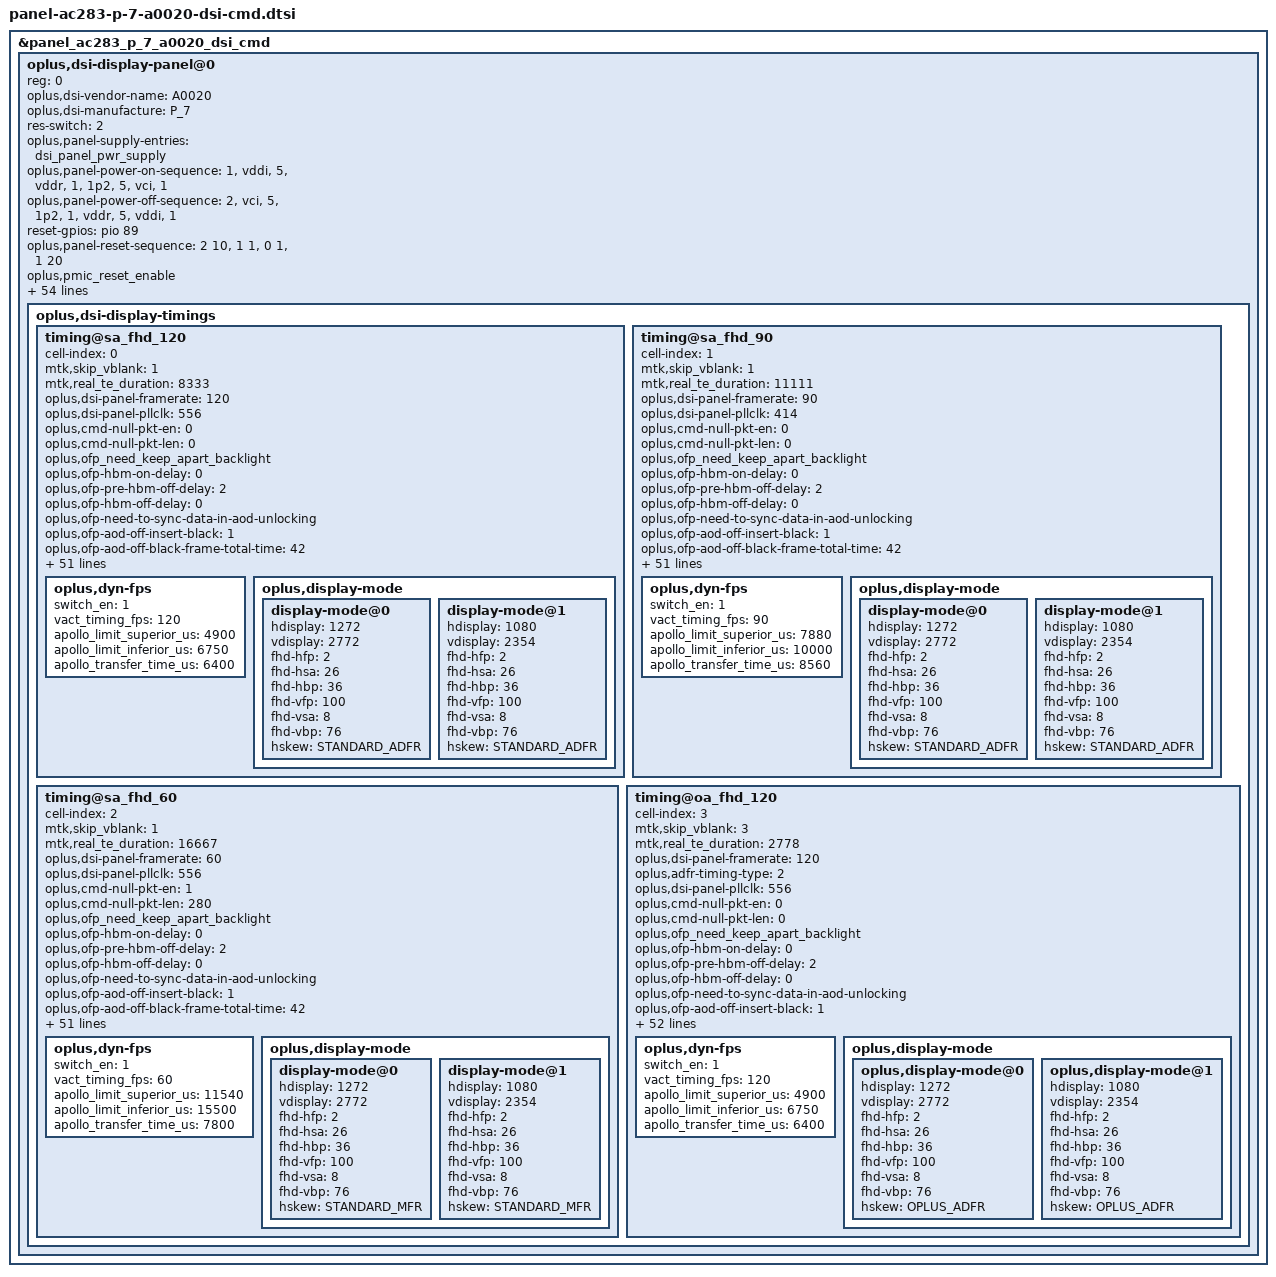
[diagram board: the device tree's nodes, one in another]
&panel_ac283_p_7_a0020_dsi_cmd {
	oplus,dsi-display-panel@0 {
		reg = <0>;
		oplus,dsi-vendor-name = "A0020";
		oplus,dsi-manufacture = "P_7";
		/* round corner */
		#include "panel-ac283-p-7-a0020-dsi-cmd-round-corner.dtsi"
		oplus,dsi-display-timings {
			timing@sa_fhd_120 {
				cell-index = <0>;
				mtk,skip_vblank = <1>;
				mtk,real_te_duration = <8333>;
				oplus,dsi-panel-framerate = <120>;
				oplus,dsi-panel-pllclk = <556>;
				oplus,cmd-null-pkt-en = <0>;
				oplus,cmd-null-pkt-len = <0>;
				/* OPLUS_FEATURE_DISPLAY_ONSCREENFINGERPRINT */
				oplus,ofp_need_keep_apart_backlight;
				oplus,ofp-hbm-on-delay = <0>;
				oplus,ofp-pre-hbm-off-delay = <2>;
				oplus,ofp-hbm-off-delay = <0>;
				oplus,ofp-need-to-sync-data-in-aod-unlocking;
				oplus,ofp-aod-off-insert-black = <1>;
				oplus,ofp-aod-off-black-frame-total-time = <42>;
				#include "panel-ac283-p-7-a0020-dsi-cmd-common.dtsi"
				oplus,dsi-timing-switch-command = [
					39 00 00 40 00 00 04 FF 5A A5 00
					15 00 00 40 00 00 02 60 00
					15 00 00 40 00 00 02 7D 00
					39 00 00 40 00 00 04 FF 5A A5 2D
					39 00 00 40 00 00 03 83 00 00
					15 00 00 00 00 00 02 F2 00
				];
				oplus,dsi-timing-switch-1pulse-command = [
				];
				oplus,dsi-on-command = [
					39 00 00 40 00 00 04 FF 5A A5 08
					15 00 00 40 00 00 02 C8 62 //OTP don’t reload
					39 00 00 40 00 00 04 FF 5A A5 21
					15 00 00 40 00 00 02 A4 38 //Flash reload
					39 00 00 40 00 00 04 FF 5A A5 23
					15 00 00 40 00 00 02 85 15 //BC reload by OTP
					39 00 00 40 00 00 04 FF 5A A5 01
					15 00 00 40 00 00 02 FB 08 //Multi TE
					// odc impro
					39 00 00 40 00 00 04 FF 5A A5 49
					39 00 00 40 00 00 0C 80 00 08 0C 1C 3C 7C 8C CC 0C 00 01
					39 00 00 40 00 00 11 81 00 00 9E 00 E5 00 6C 01 41 02 A6 03 8B 05 DD 06
					39 00 00 40 00 00 13 82 00 00 9E 00 E5 00 6C 01 41 02 A6 03 8B 05 DD 06 00 00
					15 00 00 40 00 00 02 83 07
					15 00 00 40 00 00 02 84 14
					39 00 00 40 00 00 04 85 80 00 02
					39 00 00 40 00 00 04 86 80 00 02
					39 00 00 40 00 00 04 A0 40 40 40
					39 00 00 40 00 00 04 A1 40 40 40
					39 00 00 40 00 00 04 A2 40 40 40
					15 00 00 40 00 00 02 A6 3F
					15 00 00 40 00 00 02 A7 07
					15 00 00 40 00 00 02 AD 01
					15 00 00 40 00 00 02 AE 08
					15 00 00 40 00 00 02 AF 08
					15 00 00 40 00 00 02 D9 02
					15 00 00 40 00 00 02 DA F7
					15 00 00 40 00 00 02 DB 9C
					15 00 00 40 00 00 02 DC 03
					15 00 00 40 00 00 02 DF 06
					15 00 00 40 00 00 02 E0 01
					39 00 00 40 00 00 04 FF 5A A5 5A
					39 00 00 40 00 00 04 80 00 00 00
					39 00 00 40 00 00 04 81 00 00 00
					39 00 00 40 00 00 04 82 00 00 00
					39 00 00 40 00 00 04 83 10 10 10
					39 00 00 40 00 00 04 84 00 00 00
					39 00 00 40 00 00 04 85 00 00 00
					39 00 00 40 00 00 04 86 48 02 30
					39 00 00 40 00 00 04 87 08 02 04
					39 00 00 40 00 00 04 88 08 02 04
					39 00 00 40 00 00 04 89 08 02 04
					39 00 00 40 00 00 04 8A 30 00 10
					39 00 00 40 00 00 04 8B 10 10 10
					39 00 00 40 00 00 04 8C 1A 1E 16
					39 00 00 40 00 00 04 8D 10 06 04
					39 00 00 40 00 00 04 8E 0B 06 0E
					39 00 00 40 00 00 04 8F 28 F9 0D
					39 00 00 40 00 00 04 90 12 10 10
					39 00 00 40 00 00 04 91 1D 12 15
					39 00 00 40 00 00 04 92 10 05 18
					39 00 00 40 00 00 04 93 08 FF 10
					39 00 00 40 00 00 04 94 02 FF 02
					39 00 00 40 00 00 04 95 20 0D 10
					39 00 00 40 00 00 04 96 0A 0D 0D
					39 00 00 40 00 00 04 97 0A 0D 0D
					39 00 00 40 00 00 04 98 12 14 18
					39 00 00 40 00 00 04 99 14 0E 1E
					39 00 00 40 00 00 04 9A 0A 06 0E
					39 00 00 40 00 00 04 9B 02 02 02
					39 00 00 40 00 00 04 9C 15 10 10
					39 00 00 40 00 00 04 9D 12 14 2E
					39 00 00 40 00 00 04 9E 10 26 20
					39 00 00 40 00 00 04 9F 1D 14 20
					39 00 00 40 00 00 04 A0 14 0A 1A
					39 00 00 40 00 00 04 A1 14 0A 10
					39 00 00 40 00 00 04 A2 12 08 12
					39 00 00 40 00 00 04 A3 02 02 02
					39 00 00 40 00 00 04 A4 00 00 00
					39 00 00 40 00 00 04 A5 06 F6 F5
					39 00 00 40 00 00 04 A6 00 00 00
					39 00 00 40 00 00 04 A7 02 00 00
					39 00 00 40 00 00 04 A8 00 02 00
					39 00 00 40 00 00 04 A9 00 02 00
					39 00 00 40 00 00 04 AA 08 F5 F0
					39 00 00 40 00 00 04 AB 06 06 0A
					39 00 00 40 00 00 04 AC 08 07 06
					39 00 00 40 00 00 04 AD 02 02 04
					39 00 00 40 00 00 04 AE 12 14 12
					39 00 00 40 00 00 04 AF 18 16 16
					39 00 00 40 00 00 04 B0 16 16 14
					39 00 00 40 00 00 04 B1 04 02 10
					39 00 00 40 00 00 04 B2 02 02 02
					39 00 00 40 00 00 04 B3 20 1A 2C
					39 00 00 40 00 00 04 B4 1C 16 1A
					39 00 00 40 00 00 04 B5 12 10 12
					39 00 00 40 00 00 04 B6 06 02 14
					39 00 00 40 00 00 04 B7 F6 04 02
					39 00 00 40 00 00 04 B8 F6 04 02
					39 00 00 40 00 00 04 B9 06 0D 0D
					39 00 00 40 00 00 04 BA 12 10 13
					39 00 00 40 00 00 04 BB 12 16 16
					39 00 00 40 00 00 04 BC 12 10 16
					39 00 00 40 00 00 04 BD 12 0E 12
					39 00 00 40 00 00 04 BE F6 06 02
					39 00 00 40 00 00 04 BF F6 06 02
					39 00 00 40 00 00 04 C0 12 12 12
					39 00 00 40 00 00 04 C1 12 16 10
					39 00 00 40 00 00 04 C2 12 16 1C
					39 00 00 40 00 00 04 C3 12 10 1C
					39 00 00 40 00 00 04 C4 18 18 1C
					39 00 00 40 00 00 04 C5 12 0E 16
					39 00 00 40 00 00 04 C6 16 1A 12
					39 00 00 40 00 00 04 C7 02 02 02
					39 00 00 40 00 00 04 C8 00 00 00
					39 00 00 40 00 00 04 C9 10 FC 0A
					39 00 00 40 00 00 04 CA 00 00 00
					39 00 00 40 00 00 04 CB 10 F6 0A
					39 00 00 40 00 00 04 CC 0A 08 00
					39 00 00 40 00 00 04 CD 08 06 00
					39 00 00 40 00 00 04 CE 0D 00 0A
					39 00 00 40 00 00 04 CF 04 04 04
					39 00 00 40 00 00 04 D0 04 06 06
					39 00 00 40 00 00 04 D1 02 04 04
					39 00 00 40 00 00 04 D2 16 16 14
					39 00 00 40 00 00 04 D3 16 14 14
					39 00 00 40 00 00 04 D4 14 14 12
					39 00 00 40 00 00 04 D5 10 10 10
					39 00 00 40 00 00 04 D6 02 02 02
					39 00 00 40 00 00 04 D7 12 18 16
					39 00 00 40 00 00 04 D8 12 16 12
					39 00 00 40 00 00 04 D9 10 16 12
					39 00 00 40 00 00 04 DA 0D 0A 0D
					39 00 00 40 00 00 04 DB F4 04 04
					39 00 00 40 00 00 04 DC F4 04 04
					39 00 00 40 00 00 04 DD 0D 12 10
					39 00 00 40 00 00 04 DE 0D 10 12
					39 00 00 40 00 00 04 DF 08 10 10
					39 00 00 40 00 00 04 E0 0D 20 18
					39 00 00 40 00 00 04 E1 08 14 10
					39 00 00 40 00 00 04 E2 F4 04 04
					39 00 00 40 00 00 04 E3 F4 04 04
					39 00 00 40 00 00 04 E4 0D 16 14
					39 00 00 40 00 00 04 E5 0D 12 12
					39 00 00 40 00 00 04 E6 0D 10 12
					39 00 00 40 00 00 04 E7 0D 10 12
					39 00 00 40 00 00 04 E8 0D 12 14
					39 00 00 40 00 00 04 E9 0A 10 10
					39 00 00 40 00 00 04 EA 06 10 0A
					39 00 00 40 00 00 04 EB 02 04 02
					39 00 00 40 00 00 04 FF 5A A5 5B
					39 00 00 40 00 00 04 80 00 00 00
					39 00 00 40 00 00 04 81 0D FC 02
					39 00 00 40 00 00 04 82 04 02 04
					39 00 00 40 00 00 04 83 0D 00 02
					39 00 00 40 00 00 04 84 04 04 03
					39 00 00 40 00 00 04 85 04 04 03
					39 00 00 40 00 00 04 86 03 00 01
					39 00 00 40 00 00 04 87 06 05 06
					39 00 00 40 00 00 04 88 05 03 06
					39 00 00 40 00 00 04 89 02 03 06
					39 00 00 40 00 00 04 8A 12 1A 14
					39 00 00 40 00 00 04 8B 14 18 14
					39 00 00 40 00 00 04 8C 14 18 14
					39 00 00 40 00 00 04 8D 10 12 0E
					39 00 00 40 00 00 04 8E 08 0A 08
					39 00 00 40 00 00 04 8F 10 34 2C
					39 00 00 40 00 00 04 90 10 1E 1A
					39 00 00 40 00 00 04 91 10 1E 18
					39 00 00 40 00 00 04 92 10 18 14
					39 00 00 40 00 00 04 93 F0 06 06
					39 00 00 40 00 00 04 94 F0 06 06
					39 00 00 40 00 00 04 95 06 16 16
					39 00 00 40 00 00 04 96 10 18 10
					39 00 00 40 00 00 04 97 12 16 16
					39 00 00 40 00 00 04 98 12 1E 16
					39 00 00 40 00 00 04 99 0D 14 18
					39 00 00 40 00 00 04 9A F0 06 06
					39 00 00 40 00 00 04 9B F0 06 06
					39 00 00 40 00 00 04 9C 14 18 14
					39 00 00 40 00 00 04 9D 16 16 12
					39 00 00 40 00 00 04 9E 0D 16 1E
					39 00 00 40 00 00 04 9F 0D 12 12
					39 00 00 40 00 00 04 A0 0D 16 18
					39 00 00 40 00 00 04 A1 18 16 16
					39 00 00 40 00 00 04 A2 02 02 02
					39 00 00 40 00 00 04 A3 02 02 02
					39 00 00 40 00 00 04 A4 05 00 04
					39 00 00 40 00 00 04 A5 08 03 02
					39 00 00 40 00 00 04 A6 02 02 00
					39 00 00 40 00 00 04 A7 06 03 02
					39 00 00 40 00 00 04 A8 02 02 00
					39 00 00 40 00 00 04 A9 02 02 00
					39 00 00 40 00 00 04 AA 06 06 06
					39 00 00 40 00 00 04 AB 06 06 04
					39 00 00 40 00 00 04 AC 04 06 04
					39 00 00 40 00 00 04 AD 02 02 02
					39 00 00 40 00 00 04 AE 12 12 14
					39 00 00 40 00 00 04 AF 14 16 14
					39 00 00 40 00 00 04 B0 12 14 12
					39 00 00 40 00 00 04 B1 04 02 0E
					39 00 00 40 00 00 04 B2 04 02 08
					39 00 00 40 00 00 04 B3 20 28 20
					39 00 00 40 00 00 04 B4 0D 16 12
					39 00 00 40 00 00 04 B5 0D 10 10
					39 00 00 40 00 00 04 B6 F6 02 02
					39 00 00 40 00 00 04 B7 F0 06 02
					39 00 00 40 00 00 04 B8 F0 06 02
					39 00 00 40 00 00 04 B9 0D 14 16
					39 00 00 40 00 00 04 BA 0F 12 16
					39 00 00 40 00 00 04 BB 14 16 12
					39 00 00 40 00 00 04 BC 04 08 08
					39 00 00 40 00 00 04 BD F6 02 10
					39 00 00 40 00 00 04 BE F0 06 02
					39 00 00 40 00 00 04 BF F0 06 02
					39 00 00 40 00 00 04 C0 10 16 12
					39 00 00 40 00 00 04 C1 14 16 18
					39 00 00 40 00 00 04 C2 16 14 10
					39 00 00 40 00 00 04 C3 10 12 16
					39 00 00 40 00 00 04 C4 02 0A 16
					39 00 00 40 00 00 04 C5 00 02 16
					39 00 00 40 00 00 04 C6 00 0A 14
					39 00 00 40 00 00 04 C7 02 02 02
					39 00 00 40 00 00 04 C8 06 00 06
					39 00 00 40 00 00 04 C9 05 02 02
					39 00 00 40 00 00 04 CA 00 00 00
					39 00 00 40 00 00 04 CB 04 04 03
					39 00 00 40 00 00 04 CC 02 02 02
					39 00 00 40 00 00 04 CD 00 00 00
					39 00 00 40 00 00 04 CE 0C 0C 0E
					39 00 00 40 00 00 04 CF 06 06 06
					39 00 00 40 00 00 04 D0 04 06 04
					39 00 00 40 00 00 04 D1 02 02 02
					39 00 00 40 00 00 04 D2 12 12 12
					39 00 00 40 00 00 04 D3 12 12 12
					39 00 00 40 00 00 04 D4 14 16 14
					39 00 00 40 00 00 04 D5 06 06 0A
					39 00 00 40 00 00 04 D6 02 02 06
					39 00 00 40 00 00 04 D7 1D 24 1E
					39 00 00 40 00 00 04 D8 16 1E 1A
					39 00 00 40 00 00 04 D9 12 1A 18
					39 00 00 40 00 00 04 DA 02 04 10
					39 00 00 40 00 00 04 DB FD 02 0A
					39 00 00 40 00 00 04 DC FD 00 00
					39 00 00 40 00 00 04 DD 12 18 1D
					39 00 00 40 00 00 04 DE 14 1B 1E
					39 00 00 40 00 00 04 DF 10 1A 1D
					39 00 00 40 00 00 04 E0 10 1A 14
					39 00 00 40 00 00 04 E1 02 0A 06
					39 00 00 40 00 00 04 E2 FD 02 02
					39 00 00 40 00 00 04 E3 FD 02 02
					39 00 00 40 00 00 04 E4 14 18 1C
					39 00 00 40 00 00 04 E5 10 1A 1A
					39 00 00 40 00 00 04 E6 1A 14 16
					39 00 00 40 00 00 04 E7 18 16 1C
					39 00 00 40 00 00 04 E8 14 10 10
					39 00 00 40 00 00 04 E9 0C 0E 12
					39 00 00 40 00 00 04 EA 14 12 10
					39 00 00 40 00 00 04 EB 02 02 02
					39 00 00 40 00 00 04 FF 5A A5 5C
					39 00 00 40 00 00 04 80 03 01 00
					39 00 00 40 00 00 04 81 04 02 02
					39 00 00 40 00 00 04 82 00 00 00
					39 00 00 40 00 00 04 83 01 03 02
					39 00 00 40 00 00 04 84 02 02 02
					39 00 00 40 00 00 04 85 00 00 00
					39 00 00 40 00 00 04 86 0E 10 0E
					39 00 00 40 00 00 04 87 06 06 06
					39 00 00 40 00 00 04 88 06 06 06
					39 00 00 40 00 00 04 89 02 02 02
					39 00 00 40 00 00 04 8A 16 16 14
					39 00 00 40 00 00 04 8B 16 18 14
					39 00 00 40 00 00 04 8C 14 16 12
					39 00 00 40 00 00 04 8D 0E 0E 0C
					39 00 00 40 00 00 04 8E 06 08 06
					39 00 00 40 00 00 04 8F 10 14 1C
					39 00 00 40 00 00 04 90 16 1E 18
					39 00 00 40 00 00 04 91 14 1A 16
					39 00 00 40 00 00 04 92 0D 12 10
					39 00 00 40 00 00 04 93 F2 06 04
					39 00 00 40 00 00 04 94 F2 06 04
					39 00 00 40 00 00 04 95 12 12 18
					39 00 00 40 00 00 04 96 12 10 1E
					39 00 00 40 00 00 04 97 12 18 1E
					39 00 00 40 00 00 04 98 12 1D 20
					39 00 00 40 00 00 04 99 12 1D 18
					39 00 00 40 00 00 04 9A F2 06 04
					39 00 00 40 00 00 04 9B F2 06 04
					39 00 00 40 00 00 04 9C 12 16 12
					39 00 00 40 00 00 04 9D 18 1E 12
					39 00 00 40 00 00 04 9E 14 1C 12
					39 00 00 40 00 00 04 9F 10 12 16
					39 00 00 40 00 00 04 A0 12 12 1C
					39 00 00 40 00 00 04 A1 12 12 0E
					39 00 00 40 00 00 04 A2 0E 10 0C
					39 00 00 40 00 00 04 A3 06 08 06
					39 00 00 40 00 00 04 A4 02 00 00
					39 00 00 40 00 00 04 A5 02 02 02
					39 00 00 40 00 00 04 A6 00 00 00
					39 00 00 40 00 00 04 A7 01 01 00
					39 00 00 40 00 00 04 A8 02 02 02
					39 00 00 40 00 00 04 A9 00 00 00
					39 00 00 40 00 00 04 AA 04 06 05
					39 00 00 40 00 00 04 AB 08 08 06
					39 00 00 40 00 00 04 AC 06 06 06
					39 00 00 40 00 00 04 AD 04 06 02
					39 00 00 40 00 00 04 AE 14 16 16
					39 00 00 40 00 00 04 AF 12 1A 14
					39 00 00 40 00 00 04 B0 14 16 12
					39 00 00 40 00 00 04 B1 04 04 0C
					39 00 00 40 00 00 04 B2 06 02 06
					39 00 00 40 00 00 04 B3 18 1A 1C
					39 00 00 40 00 00 04 B4 1A 1E 18
					39 00 00 40 00 00 04 B5 18 1A 14
					39 00 00 40 00 00 04 B6 06 04 0E
					39 00 00 40 00 00 04 B7 00 02 02
					39 00 00 40 00 00 04 B8 FE 00 00
					39 00 00 40 00 00 04 B9 0D 1D 1C
					39 00 00 40 00 00 04 BA 12 1D 1E
					39 00 00 40 00 00 04 BB 14 13 15
					39 00 00 40 00 00 04 BC 04 0C 0B
					39 00 00 40 00 00 04 BD 04 0C 0B
					39 00 00 40 00 00 04 BE FE 02 02
					39 00 00 40 00 00 04 BF FE 02 02
					39 00 00 40 00 00 04 C0 12 18 16
					39 00 00 40 00 00 04 C1 16 12 10
					39 00 00 40 00 00 04 C2 1C 16 1C
					39 00 00 40 00 00 04 C3 10 14 16
					39 00 00 40 00 00 04 C4 14 0A 1C
					39 00 00 40 00 00 04 C5 0E 08 10
					39 00 00 40 00 00 04 C6 0A 04 0A
					39 00 00 40 00 00 04 C7 00 00 00
					39 00 00 40 00 00 04 C8 04 04 04
					39 00 00 40 00 00 04 C9 0A 04 04
					39 00 00 40 00 00 04 CA 0A 04 04
					39 00 00 40 00 00 04 CB 0A 04 04
					39 00 00 40 00 00 04 CC 00 00 00
					39 00 00 40 00 00 04 CD 01 01 01
					39 00 00 40 00 00 04 CE 02 00 00
					39 00 00 40 00 00 04 CF 02 01 01
					39 00 00 00 00 00 04 FF 5A A5 00
					// ctb impro
					39 00 00 40 00 00 04 FF 5A A5 31
					39 00 00 40 00 00 0B 90 02 03 05 07 0A 02 03 05 07 0A
					39 00 00 40 00 00 19 8C 21 13 0C 0B 08 04 00 00 00 00 00 00 00 00 00 00 00 00 00 00 00 00 00 00
					39 00 00 40 00 00 1A 8D 16 0A 06 00 00 00 00 00 00 00 00 00 00 00 00 00 00 00 00 00 00 00 00 00 00
					39 00 00 40 00 00 09 8F 40 40 40 40 40 40 40 40
					15 00 00 40 00 00 02 D0 81
					39 00 00 40 00 00 13 80 F0 92 24 18 02 FE E8 DC 6E E0 10 0A 05 00 00 FA F6 F3
					39 00 00 40 00 00 13 81 F0 5C 24 16 02 FE EA DC A4 E0 0A 09 05 00 00 FE FB F0
					39 00 00 40 00 00 13 82 F0 48 24 11 02 FE EF DC B8 E0 0E 09 05 00 00 FF F7 F4
					39 00 00 40 00 00 13 83 F0 44 2C 10 02 FE F0 D4 BC E0 13 0D 05 00 00 FF FA F8
					39 00 00 40 00 00 13 86 F0 92 24 18 02 FE E8 DC 6E E0 10 0A 05 00 00 FA F6 F3
					39 00 00 40 00 00 13 87 F0 5C 24 16 02 FE EA DC A4 E0 0A 09 05 00 00 FE FB F0
					39 00 00 40 00 00 13 88 F0 48 24 11 02 FE EF DC B8 E0 0E 09 05 00 00 FF F7 F4
					39 00 00 40 00 00 13 89 F0 44 2C 10 02 FE F0 D4 BC E0 13 0D 05 00 00 FF FA F8
					15 00 00 40 00 00 02 D0 80
					39 00 00 00 01 00 04 FF 5A A5 00
					// te shift on
					39 00 00 40 00 00 04 FF 5A A5 02
					39 00 00 40 00 00 03 AB AF 82
					// ddic corner Hole
					39 00 00 40 00 00 04 FF 5A A5 13
					39 00 00 40 00 00 02 F9 4C //HOLE OFF
					39 00 00 40 00 00 04 FF 5A A5 17
					15 00 00 40 00 00 02 A0 0E //RCN OFF
					// pps table
					39 00 00 40 00 00 04 FF 5A A5 07
					15 00 00 40 00 00 02 8A 01
					39 00 00 40 00 00 03 8B 21 E0
					39 00 00 40 00 00 64 80 00 00 00 00 00 12 00 00 AB 30 80 0A D4 04 F8 00 16 02 7C 02 7C 02 00 02 59 00 20 02 2E 00 08 00 0D 04 F4 03 ED 18 00 10 F0 07 10 20 00 06 0F 0F 33 0E 1C 2A 38 46 54 62 69 70 77 79 7B 7D 7E 02 02 22 00 2A 40 2A BE 3A FC 3A FA 3A F8 3B 38 3B 78 3B B6 4B B6 4B F4 4B F4 6C 34 84 74 00 00 00 00 00 00
					39 00 00 40 00 00 64 81 00 00 00 00 00 12 00 00 AB 21 00 0A D4 04 F8 00 16 02 7C 02 7C 01 55 01 D7 00 0A 01 2D 00 35 00 0D 04 F4 16 3B 08 00 0C 00 07 10 20 00 06 0F 0F 33 0E 1C 2A 38 46 54 62 69 70 77 79 7B 7D 7E 00 82 11 40 19 C0 22 3E 32 7C 3A BA 3A F8 3B 38 3B 38 3B 76 4B 76 4B 74 4B 74 5B B4 73 F4 01 00 00 00 00 00
					39 00 00 40 00 00 04 FF 5A A5 07
					15 00 00 40 00 00 02 91 00         //Ycrcb
					39 00 00 40 00 00 04 FF 5A A5 14
					15 00 00 40 00 00 02 82 01       //SPR IN AP ON
					39 00 00 40 00 00 04 FF 5A A5 14
					15 00 00 40 00 00 02 80 00      //DDIC SPR OFF
					39 00 00 40 00 00 04 FF 5A A5 00
					39 00 00 40 00 00 04 FF 5A A5 06
					15 00 00 40 00 00 02 A0 00 //ESD fixed
					15 00 00 40 00 00 02 C6 01 //1bit ESD check
					39 00 00 40 00 00 04 FF 5A A5 08
					15 00 00 40 00 00 02 D2 05
					15 00 00 40 00 00 02 D3 01
					15 00 00 40 00 00 02 E0 22 // crc reset
					39 00 00 40 00 00 09 ED FF FF FF FF FF FF 45 FF
					39 00 00 40 00 00 09 EE FF FD FF FD F9 FA BE 76
					// osc fixed Auto trim TE
					39 00 00 40 00 00 04 FF 5A A5 22
					39 00 00 40 00 00 08 D8 00 FF 11 10 3C 18 18
					39 00 00 40 00 00 08 D9 00 BE 11 10 3C 12 12
					39 00 00 40 00 00 0A DC 84 94 BB 00 20 C4 A1 CC 10
					15 00 00 40 00 00 02 DD 01
					15 00 00 40 00 00 02 DE F1
					15 00 00 40 00 00 02 DF 80
					39 00 00 40 00 00 07 E0 02 00 5F 21 00 28
					39 00 00 40 00 00 04 FF 5A A5 00
					15 00 00 40 00 00 02 7D 00
					39 00 00 40 00 00 04 FF 5A A5 00
					15 00 00 40 00 00 02 5E 01
					15 00 00 40 00 00 02 60 00
					15 00 00 40 00 00 02 61 07
					15 00 00 40 00 00 02 6D 01
					15 00 00 40 00 00 02 35 00
					15 00 00 40 00 00 02 53 20
					// timing switch
					39 00 00 40 00 00 04 FF 5A A5 00
					15 00 00 40 00 00 02 60 00
					15 00 00 40 00 00 02 7D 00
					39 00 00 40 00 00 04 FF 5A A5 2D
					39 00 00 40 00 00 03 83 00 00
					15 00 00 40 00 00 02 F2 00
					// odc on
					39 00 00 40 00 00 04 FF 5A A5 49
					15 00 00 40 00 00 02 E0 01
					// dvdd sleep in
					39 00 00 40 00 00 04 FF 5A A5 1F
					39 00 00 40 00 00 05 96 15 30 03 01
					39 00 00 40 00 00 19 83 20 23 21 1E 1F 00 00 00 1E 1F 00 00 20 1F 20 23 20 00 00 00 00 00 00 00
					39 00 00 40 00 00 19 8F 0F 06 78 0E 11 00 00 00 0E 11 00 00 00 10 02 06 06 00 00 00 00 00 00 00
					39 00 00 40 00 00 04 FF 5A A5 00
					// pull dowm pmic
					39 00 00 40 00 00 04 FF 5A A5 1C
					39 00 00 40 00 00 16 E1 10 80 9A 65 59 54 69 95 56 6A 55 99 9A 55 55 25 58 55 66 A2 00
					39 00 00 40 00 00 04 FF 5A A5 05
					15 00 00 40 00 00 02 83 01
					// LGOCB change to 30
					39 00 00 40 00 00 04 FF 5A A5 53
					39 00 00 40 00 00 1F A2 10 10 10 10 10 10 10 10 30 30 10 10 10 10 10 10 10 10 30 30 10 10 10 10 10 10 10 10 30 30
					39 00 00 00 00 00 04 FF 5A A5 00
					//Light On
					39 00 00 00 78 00 01 11 // Sleep out
					39 00 00 40 00 00 04 FF 5A A5 00
					39 00 00 00 00 00 01 29 // Display out
				];
				oplus,dsi-aod-off-command = [
					39 00 00 00 00 00 04 FF 5A A5 00
					39 00 00 00 00 00 02 38 00
					39 00 00 00 00 00 05 51 00 00 00 00
					39 00 00 00 00 00 04 FF 5A A5 51
					39 00 00 00 00 00 07 A6 C7 C3 C3 C3 22 22
					39 00 00 00 00 00 04 FF 5A A5 52
					39 00 00 00 00 00 07 86 46 46 46 46 00 00
					39 00 00 00 00 00 04 FF 5A A5 02
					39 00 00 00 00 00 03 AB AF 82
				];
				oplus,dsi-ultra-low-power-aod-on-command = [
					39 00 00 00 00 00 04 FF 5A A5 2D
					39 00 00 00 00 00 03 8A 02 00
					39 00 00 00 00 00 04 FF 5A A5 00
				];
				oplus,dsi-ultra-low-power-aod-off-command = [
					39 00 00 00 00 00 04 FF 5A A5 2D
					39 00 00 00 00 00 03 8A 00 00
					39 00 00 00 00 00 04 FF 5A A5 00
				];
				oplus,dsi-hbm-on-command = [
					39 00 00 00 00 00 03 51 0E 7A
				];
				oplus,dsi-hbm-off-command = [
					39 00 00 00 00 00 03 51 0D BB
				];
				oplus,dsi-pwm-switch-1to3pul-command = [
				];
				oplus,dsi-pwm-switch-3to1pul-command = [
				];
				oplus,dsi-adfr-min-fps-120hz-command = [
					39 00 00 40 00 00 04 FF 5A A5 2D
					39 00 00 40 00 00 03 83 00 00
					39 00 00 00 00 00 04 FF 5A A5 00
				];
				oplus,dsi-adfr-min-fps-30hz-command = [
					39 00 00 40 00 00 04 FF 5A A5 2D
					39 00 00 40 00 00 03 83 03 00
					39 00 00 00 00 00 04 FF 5A A5 00
				];
				oplus,dsi-adfr-min-fps-10hz-command = [
					39 00 00 40 00 00 04 FF 5A A5 2D
					39 00 00 40 00 00 03 83 0B 00
					39 00 00 00 00 00 04 FF 5A A5 00
				];
				oplus,dsi-adfr-min-fps-1hz-command = [
					39 00 00 40 00 00 04 FF 5A A5 2D
					39 00 00 40 00 00 03 83 77 00
					39 00 00 00 00 00 04 FF 5A A5 00
				];
				oplus,dsi-timing-switch-command-state = "dsi_hs_mode";
				oplus,dsi-timing-switch-1pulse-command-state = "dsi_hs_mode";
				oplus,dsi-on-command-state = "dsi_lp_mode";
				oplus,dsi-aod-off-command-state = "dsi_ls_mode";
				oplus,dsi-ultra-low-power-aod-on-command-state = "dsi_ls_mode";
				oplus,dsi-ultra-low-power-aod-off-command-state = "dsi_ls_mode";
				oplus,dsi-hbm-on-command-state = "dsi_hs_mode";
				oplus,dsi-hbm-off-command-state = "dsi_hs_mode";
				oplus,dsi-pwm-switch-1to3pul-command-state = "dsi_hs_mode";
				oplus,dsi-pwm-switch-3to1pul-command-state = "dsi_hs_mode";
				oplus,dsi-adfr-min-fps-120hz-command-state = "dsi_hs_mode";
				oplus,dsi-adfr-min-fps-30hz-command-state = "dsi_hs_mode";
				oplus,dsi-adfr-min-fps-10hz-command-state = "dsi_hs_mode";
				oplus,dsi-adfr-min-fps-1hz-command-state = "dsi_hs_mode";
				oplus,dsc-params-entries = <&dsc_params>;
				oplus,spr-params-entries = <&spr_params>;
				oplus,dyn-fps {
					switch_en = <1>;
					vact_timing_fps = <120>;
					apollo_limit_superior_us = <4900>;
					apollo_limit_inferior_us = <6750>;
					apollo_transfer_time_us = <6400>;
				};
				oplus,display-mode {
					display-mode@0 {
						hdisplay = <1272>;
						vdisplay = <2772>;
						fhd-hfp = <2>;
						fhd-hsa = <26>;
						fhd-hbp = <36>;
						fhd-vfp = <100>;
						fhd-vsa = <8>;
						fhd-vbp = <76>;
						hskew = <STANDARD_ADFR>;
					};
					display-mode@1 {
						hdisplay = <1080>;
						vdisplay = <2354>;
						fhd-hfp = <2>;
						fhd-hsa = <26>;
						fhd-hbp = <36>;
						fhd-vfp = <100>;
						fhd-vsa = <8>;
						fhd-vbp = <76>;
						hskew = <STANDARD_ADFR>;
					};
				};
			};
			timing@sa_fhd_90 {
				cell-index = <1>;
				mtk,skip_vblank = <1>;
				mtk,real_te_duration = <11111>;
				oplus,dsi-panel-framerate = <90>;
				oplus,dsi-panel-pllclk = <414>;
				oplus,cmd-null-pkt-en = <0>;
				oplus,cmd-null-pkt-len = <0>;
				/* OPLUS_FEATURE_DISPLAY_ONSCREENFINGERPRINT */
				oplus,ofp_need_keep_apart_backlight;
				oplus,ofp-hbm-on-delay = <0>;
				oplus,ofp-pre-hbm-off-delay = <2>;
				oplus,ofp-hbm-off-delay = <0>;
				oplus,ofp-need-to-sync-data-in-aod-unlocking;
				oplus,ofp-aod-off-insert-black = <1>;
				oplus,ofp-aod-off-black-frame-total-time = <42>;
				#include "panel-ac283-p-7-a0020-dsi-cmd-common.dtsi"
				oplus,dsi-timing-switch-command = [
					39 00 00 40 00 00 04 FF 5A A5 00
					15 00 00 40 00 00 02 60 02
					15 00 00 40 00 00 02 7D 01
					39 00 00 40 00 00 04 FF 5A A5 2D
					39 00 00 00 00 00 03 85 00 00
				];
				oplus,dsi-timing-switch-1pulse-command = [
				];
				oplus,dsi-on-command = [
					39 00 00 40 00 00 04 FF 5A A5 08
					15 00 00 40 00 00 02 C8 62 //OTP don’t reload
					39 00 00 40 00 00 04 FF 5A A5 21
					15 00 00 40 00 00 02 A4 38 //Flash reload
					39 00 00 40 00 00 04 FF 5A A5 23
					15 00 00 40 00 00 02 85 15 //BC reload by OTP
					39 00 00 40 00 00 04 FF 5A A5 01
					15 00 00 40 00 00 02 FB 08 //Multi TE
					// odc impro
					39 00 00 40 00 00 04 FF 5A A5 49
					39 00 00 40 00 00 0C 80 00 08 0C 1C 3C 7C 8C CC 0C 00 01
					39 00 00 40 00 00 11 81 00 00 9E 00 E5 00 6C 01 41 02 A6 03 8B 05 DD 06
					39 00 00 40 00 00 13 82 00 00 9E 00 E5 00 6C 01 41 02 A6 03 8B 05 DD 06 00 00
					15 00 00 40 00 00 02 83 07
					15 00 00 40 00 00 02 84 14
					39 00 00 40 00 00 04 85 80 00 02
					39 00 00 40 00 00 04 86 80 00 02
					39 00 00 40 00 00 04 A0 40 40 40
					39 00 00 40 00 00 04 A1 40 40 40
					39 00 00 40 00 00 04 A2 40 40 40
					15 00 00 40 00 00 02 A6 3F
					15 00 00 40 00 00 02 A7 07
					15 00 00 40 00 00 02 AD 01
					15 00 00 40 00 00 02 AE 08
					15 00 00 40 00 00 02 AF 08
					15 00 00 40 00 00 02 D9 02
					15 00 00 40 00 00 02 DA F7
					15 00 00 40 00 00 02 DB 9C
					15 00 00 40 00 00 02 DC 03
					15 00 00 40 00 00 02 DF 06
					15 00 00 40 00 00 02 E0 01
					39 00 00 40 00 00 04 FF 5A A5 5A
					39 00 00 40 00 00 04 80 00 00 00
					39 00 00 40 00 00 04 81 00 00 00
					39 00 00 40 00 00 04 82 00 00 00
					39 00 00 40 00 00 04 83 10 10 10
					39 00 00 40 00 00 04 84 00 00 00
					39 00 00 40 00 00 04 85 00 00 00
					39 00 00 40 00 00 04 86 48 02 30
					39 00 00 40 00 00 04 87 08 02 04
					39 00 00 40 00 00 04 88 08 02 04
					39 00 00 40 00 00 04 89 08 02 04
					39 00 00 40 00 00 04 8A 30 00 10
					39 00 00 40 00 00 04 8B 10 10 10
					39 00 00 40 00 00 04 8C 1A 1E 16
					39 00 00 40 00 00 04 8D 10 06 04
					39 00 00 40 00 00 04 8E 0B 06 0E
					39 00 00 40 00 00 04 8F 28 F9 0D
					39 00 00 40 00 00 04 90 12 10 10
					39 00 00 40 00 00 04 91 1D 12 15
					39 00 00 40 00 00 04 92 10 05 18
					39 00 00 40 00 00 04 93 08 FF 10
					39 00 00 40 00 00 04 94 02 FF 02
					39 00 00 40 00 00 04 95 20 0D 10
					39 00 00 40 00 00 04 96 0A 0D 0D
					39 00 00 40 00 00 04 97 0A 0D 0D
					39 00 00 40 00 00 04 98 12 14 18
					39 00 00 40 00 00 04 99 14 0E 1E
					39 00 00 40 00 00 04 9A 0A 06 0E
					39 00 00 40 00 00 04 9B 02 02 02
					39 00 00 40 00 00 04 9C 15 10 10
					39 00 00 40 00 00 04 9D 12 14 2E
					39 00 00 40 00 00 04 9E 10 26 20
					39 00 00 40 00 00 04 9F 1D 14 20
					39 00 00 40 00 00 04 A0 14 0A 1A
					39 00 00 40 00 00 04 A1 14 0A 10
					39 00 00 40 00 00 04 A2 12 08 12
					39 00 00 40 00 00 04 A3 02 02 02
					39 00 00 40 00 00 04 A4 00 00 00
					39 00 00 40 00 00 04 A5 06 F6 F5
					39 00 00 40 00 00 04 A6 00 00 00
					39 00 00 40 00 00 04 A7 02 00 00
					39 00 00 40 00 00 04 A8 00 02 00
					39 00 00 40 00 00 04 A9 00 02 00
					39 00 00 40 00 00 04 AA 08 F5 F0
					39 00 00 40 00 00 04 AB 06 06 0A
					39 00 00 40 00 00 04 AC 08 07 06
					39 00 00 40 00 00 04 AD 02 02 04
					39 00 00 40 00 00 04 AE 12 14 12
					39 00 00 40 00 00 04 AF 18 16 16
					39 00 00 40 00 00 04 B0 16 16 14
					39 00 00 40 00 00 04 B1 04 02 10
					39 00 00 40 00 00 04 B2 02 02 02
					39 00 00 40 00 00 04 B3 20 1A 2C
					39 00 00 40 00 00 04 B4 1C 16 1A
					39 00 00 40 00 00 04 B5 12 10 12
					39 00 00 40 00 00 04 B6 06 02 14
					39 00 00 40 00 00 04 B7 F6 04 02
					39 00 00 40 00 00 04 B8 F6 04 02
					39 00 00 40 00 00 04 B9 06 0D 0D
					39 00 00 40 00 00 04 BA 12 10 13
					39 00 00 40 00 00 04 BB 12 16 16
					39 00 00 40 00 00 04 BC 12 10 16
					39 00 00 40 00 00 04 BD 12 0E 12
					39 00 00 40 00 00 04 BE F6 06 02
					39 00 00 40 00 00 04 BF F6 06 02
					39 00 00 40 00 00 04 C0 12 12 12
					39 00 00 40 00 00 04 C1 12 16 10
					39 00 00 40 00 00 04 C2 12 16 1C
					39 00 00 40 00 00 04 C3 12 10 1C
					39 00 00 40 00 00 04 C4 18 18 1C
					39 00 00 40 00 00 04 C5 12 0E 16
					39 00 00 40 00 00 04 C6 16 1A 12
					39 00 00 40 00 00 04 C7 02 02 02
					39 00 00 40 00 00 04 C8 00 00 00
					39 00 00 40 00 00 04 C9 10 FC 0A
					39 00 00 40 00 00 04 CA 00 00 00
					39 00 00 40 00 00 04 CB 10 F6 0A
					39 00 00 40 00 00 04 CC 0A 08 00
					39 00 00 40 00 00 04 CD 08 06 00
					39 00 00 40 00 00 04 CE 0D 00 0A
					39 00 00 40 00 00 04 CF 04 04 04
					39 00 00 40 00 00 04 D0 04 06 06
					39 00 00 40 00 00 04 D1 02 04 04
					39 00 00 40 00 00 04 D2 16 16 14
					39 00 00 40 00 00 04 D3 16 14 14
					39 00 00 40 00 00 04 D4 14 14 12
					39 00 00 40 00 00 04 D5 10 10 10
					39 00 00 40 00 00 04 D6 02 02 02
					39 00 00 40 00 00 04 D7 12 18 16
					39 00 00 40 00 00 04 D8 12 16 12
					39 00 00 40 00 00 04 D9 10 16 12
					39 00 00 40 00 00 04 DA 0D 0A 0D
					39 00 00 40 00 00 04 DB F4 04 04
					39 00 00 40 00 00 04 DC F4 04 04
					39 00 00 40 00 00 04 DD 0D 12 10
					39 00 00 40 00 00 04 DE 0D 10 12
					39 00 00 40 00 00 04 DF 08 10 10
					39 00 00 40 00 00 04 E0 0D 20 18
					39 00 00 40 00 00 04 E1 08 14 10
					39 00 00 40 00 00 04 E2 F4 04 04
					39 00 00 40 00 00 04 E3 F4 04 04
					39 00 00 40 00 00 04 E4 0D 16 14
					39 00 00 40 00 00 04 E5 0D 12 12
					39 00 00 40 00 00 04 E6 0D 10 12
					39 00 00 40 00 00 04 E7 0D 10 12
					39 00 00 40 00 00 04 E8 0D 12 14
					39 00 00 40 00 00 04 E9 0A 10 10
					39 00 00 40 00 00 04 EA 06 10 0A
					39 00 00 40 00 00 04 EB 02 04 02
					39 00 00 40 00 00 04 FF 5A A5 5B
					39 00 00 40 00 00 04 80 00 00 00
					39 00 00 40 00 00 04 81 0D FC 02
					39 00 00 40 00 00 04 82 04 02 04
					39 00 00 40 00 00 04 83 0D 00 02
					39 00 00 40 00 00 04 84 04 04 03
					39 00 00 40 00 00 04 85 04 04 03
					39 00 00 40 00 00 04 86 03 00 01
					39 00 00 40 00 00 04 87 06 05 06
					39 00 00 40 00 00 04 88 05 03 06
					39 00 00 40 00 00 04 89 02 03 06
					39 00 00 40 00 00 04 8A 12 1A 14
					39 00 00 40 00 00 04 8B 14 18 14
					39 00 00 40 00 00 04 8C 14 18 14
					39 00 00 40 00 00 04 8D 10 12 0E
					39 00 00 40 00 00 04 8E 08 0A 08
					39 00 00 40 00 00 04 8F 10 34 2C
					39 00 00 40 00 00 04 90 10 1E 1A
					39 00 00 40 00 00 04 91 10 1E 18
					39 00 00 40 00 00 04 92 10 18 14
					39 00 00 40 00 00 04 93 F0 06 06
					39 00 00 40 00 00 04 94 F0 06 06
					39 00 00 40 00 00 04 95 06 16 16
					39 00 00 40 00 00 04 96 10 18 10
					39 00 00 40 00 00 04 97 12 16 16
					39 00 00 40 00 00 04 98 12 1E 16
					39 00 00 40 00 00 04 99 0D 14 18
					39 00 00 40 00 00 04 9A F0 06 06
					39 00 00 40 00 00 04 9B F0 06 06
					39 00 00 40 00 00 04 9C 14 18 14
					39 00 00 40 00 00 04 9D 16 16 12
					39 00 00 40 00 00 04 9E 0D 16 1E
					39 00 00 40 00 00 04 9F 0D 12 12
					39 00 00 40 00 00 04 A0 0D 16 18
					39 00 00 40 00 00 04 A1 18 16 16
					39 00 00 40 00 00 04 A2 02 02 02
					39 00 00 40 00 00 04 A3 02 02 02
					39 00 00 40 00 00 04 A4 05 00 04
					39 00 00 40 00 00 04 A5 08 03 02
					39 00 00 40 00 00 04 A6 02 02 00
					39 00 00 40 00 00 04 A7 06 03 02
					39 00 00 40 00 00 04 A8 02 02 00
					39 00 00 40 00 00 04 A9 02 02 00
					39 00 00 40 00 00 04 AA 06 06 06
					39 00 00 40 00 00 04 AB 06 06 04
					39 00 00 40 00 00 04 AC 04 06 04
					39 00 00 40 00 00 04 AD 02 02 02
					39 00 00 40 00 00 04 AE 12 12 14
					39 00 00 40 00 00 04 AF 14 16 14
					39 00 00 40 00 00 04 B0 12 14 12
					39 00 00 40 00 00 04 B1 04 02 0E
					39 00 00 40 00 00 04 B2 04 02 08
					39 00 00 40 00 00 04 B3 20 28 20
					39 00 00 40 00 00 04 B4 0D 16 12
					39 00 00 40 00 00 04 B5 0D 10 10
					39 00 00 40 00 00 04 B6 F6 02 02
					39 00 00 40 00 00 04 B7 F0 06 02
					39 00 00 40 00 00 04 B8 F0 06 02
					39 00 00 40 00 00 04 B9 0D 14 16
					39 00 00 40 00 00 04 BA 0F 12 16
					39 00 00 40 00 00 04 BB 14 16 12
					39 00 00 40 00 00 04 BC 04 08 08
					39 00 00 40 00 00 04 BD F6 02 10
					39 00 00 40 00 00 04 BE F0 06 02
					39 00 00 40 00 00 04 BF F0 06 02
					39 00 00 40 00 00 04 C0 10 16 12
					39 00 00 40 00 00 04 C1 14 16 18
					39 00 00 40 00 00 04 C2 16 14 10
					39 00 00 40 00 00 04 C3 10 12 16
					39 00 00 40 00 00 04 C4 02 0A 16
					39 00 00 40 00 00 04 C5 00 02 16
					39 00 00 40 00 00 04 C6 00 0A 14
					39 00 00 40 00 00 04 C7 02 02 02
					39 00 00 40 00 00 04 C8 06 00 06
					39 00 00 40 00 00 04 C9 05 02 02
					39 00 00 40 00 00 04 CA 00 00 00
					39 00 00 40 00 00 04 CB 04 04 03
					39 00 00 40 00 00 04 CC 02 02 02
					39 00 00 40 00 00 04 CD 00 00 00
					39 00 00 40 00 00 04 CE 0C 0C 0E
					39 00 00 40 00 00 04 CF 06 06 06
					39 00 00 40 00 00 04 D0 04 06 04
					39 00 00 40 00 00 04 D1 02 02 02
					39 00 00 40 00 00 04 D2 12 12 12
					39 00 00 40 00 00 04 D3 12 12 12
					39 00 00 40 00 00 04 D4 14 16 14
					39 00 00 40 00 00 04 D5 06 06 0A
					39 00 00 40 00 00 04 D6 02 02 06
					39 00 00 40 00 00 04 D7 1D 24 1E
					39 00 00 40 00 00 04 D8 16 1E 1A
					39 00 00 40 00 00 04 D9 12 1A 18
					39 00 00 40 00 00 04 DA 02 04 10
					39 00 00 40 00 00 04 DB FD 02 0A
					39 00 00 40 00 00 04 DC FD 00 00
					39 00 00 40 00 00 04 DD 12 18 1D
					39 00 00 40 00 00 04 DE 14 1B 1E
					39 00 00 40 00 00 04 DF 10 1A 1D
					39 00 00 40 00 00 04 E0 10 1A 14
					39 00 00 40 00 00 04 E1 02 0A 06
					39 00 00 40 00 00 04 E2 FD 02 02
					39 00 00 40 00 00 04 E3 FD 02 02
					39 00 00 40 00 00 04 E4 14 18 1C
					39 00 00 40 00 00 04 E5 10 1A 1A
					39 00 00 40 00 00 04 E6 1A 14 16
					39 00 00 40 00 00 04 E7 18 16 1C
					39 00 00 40 00 00 04 E8 14 10 10
					39 00 00 40 00 00 04 E9 0C 0E 12
					39 00 00 40 00 00 04 EA 14 12 10
					39 00 00 40 00 00 04 EB 02 02 02
					39 00 00 40 00 00 04 FF 5A A5 5C
					39 00 00 40 00 00 04 80 03 01 00
					39 00 00 40 00 00 04 81 04 02 02
					39 00 00 40 00 00 04 82 00 00 00
					39 00 00 40 00 00 04 83 01 03 02
					39 00 00 40 00 00 04 84 02 02 02
					39 00 00 40 00 00 04 85 00 00 00
					39 00 00 40 00 00 04 86 0E 10 0E
					39 00 00 40 00 00 04 87 06 06 06
					39 00 00 40 00 00 04 88 06 06 06
					39 00 00 40 00 00 04 89 02 02 02
					39 00 00 40 00 00 04 8A 16 16 14
					39 00 00 40 00 00 04 8B 16 18 14
					39 00 00 40 00 00 04 8C 14 16 12
					39 00 00 40 00 00 04 8D 0E 0E 0C
					39 00 00 40 00 00 04 8E 06 08 06
					39 00 00 40 00 00 04 8F 10 14 1C
					39 00 00 40 00 00 04 90 16 1E 18
					39 00 00 40 00 00 04 91 14 1A 16
					39 00 00 40 00 00 04 92 0D 12 10
					39 00 00 40 00 00 04 93 F2 06 04
					39 00 00 40 00 00 04 94 F2 06 04
					39 00 00 40 00 00 04 95 12 12 18
					39 00 00 40 00 00 04 96 12 10 1E
					39 00 00 40 00 00 04 97 12 18 1E
					39 00 00 40 00 00 04 98 12 1D 20
					39 00 00 40 00 00 04 99 12 1D 18
					39 00 00 40 00 00 04 9A F2 06 04
					39 00 00 40 00 00 04 9B F2 06 04
					39 00 00 40 00 00 04 9C 12 16 12
					39 00 00 40 00 00 04 9D 18 1E 12
					39 00 00 40 00 00 04 9E 14 1C 12
					39 00 00 40 00 00 04 9F 10 12 16
					39 00 00 40 00 00 04 A0 12 12 1C
					39 00 00 40 00 00 04 A1 12 12 0E
					39 00 00 40 00 00 04 A2 0E 10 0C
					39 00 00 40 00 00 04 A3 06 08 06
					39 00 00 40 00 00 04 A4 02 00 00
					39 00 00 40 00 00 04 A5 02 02 02
					39 00 00 40 00 00 04 A6 00 00 00
					39 00 00 40 00 00 04 A7 01 01 00
					39 00 00 40 00 00 04 A8 02 02 02
					39 00 00 40 00 00 04 A9 00 00 00
					39 00 00 40 00 00 04 AA 04 06 05
					39 00 00 40 00 00 04 AB 08 08 06
					39 00 00 40 00 00 04 AC 06 06 06
					39 00 00 40 00 00 04 AD 04 06 02
					39 00 00 40 00 00 04 AE 14 16 16
					39 00 00 40 00 00 04 AF 12 1A 14
					39 00 00 40 00 00 04 B0 14 16 12
					39 00 00 40 00 00 04 B1 04 04 0C
					39 00 00 40 00 00 04 B2 06 02 06
					39 00 00 40 00 00 04 B3 18 1A 1C
					39 00 00 40 00 00 04 B4 1A 1E 18
					39 00 00 40 00 00 04 B5 18 1A 14
					39 00 00 40 00 00 04 B6 06 04 0E
					39 00 00 40 00 00 04 B7 00 02 02
					39 00 00 40 00 00 04 B8 FE 00 00
					39 00 00 40 00 00 04 B9 0D 1D 1C
					39 00 00 40 00 00 04 BA 12 1D 1E
					39 00 00 40 00 00 04 BB 14 13 15
					39 00 00 40 00 00 04 BC 04 0C 0B
					39 00 00 40 00 00 04 BD 04 0C 0B
					39 00 00 40 00 00 04 BE FE 02 02
					39 00 00 40 00 00 04 BF FE 02 02
					39 00 00 40 00 00 04 C0 12 18 16
					39 00 00 40 00 00 04 C1 16 12 10
					39 00 00 40 00 00 04 C2 1C 16 1C
					39 00 00 40 00 00 04 C3 10 14 16
					39 00 00 40 00 00 04 C4 14 0A 1C
					39 00 00 40 00 00 04 C5 0E 08 10
					39 00 00 40 00 00 04 C6 0A 04 0A
					39 00 00 40 00 00 04 C7 00 00 00
					39 00 00 40 00 00 04 C8 04 04 04
					39 00 00 40 00 00 04 C9 0A 04 04
					39 00 00 40 00 00 04 CA 0A 04 04
					39 00 00 40 00 00 04 CB 0A 04 04
					39 00 00 40 00 00 04 CC 00 00 00
					39 00 00 40 00 00 04 CD 01 01 01
					39 00 00 40 00 00 04 CE 02 00 00
					39 00 00 40 00 00 04 CF 02 01 01
					39 00 00 00 00 00 04 FF 5A A5 00
					// ctb impro
					39 00 00 40 00 00 04 FF 5A A5 31
					39 00 00 40 00 00 0B 90 02 03 05 07 0A 02 03 05 07 0A
					39 00 00 40 00 00 19 8C 21 13 0C 0B 08 04 00 00 00 00 00 00 00 00 00 00 00 00 00 00 00 00 00 00
					39 00 00 40 00 00 1A 8D 16 0A 06 00 00 00 00 00 00 00 00 00 00 00 00 00 00 00 00 00 00 00 00 00 00
					39 00 00 40 00 00 09 8F 40 40 40 40 40 40 40 40
					15 00 00 40 00 00 02 D0 81
					39 00 00 40 00 00 13 80 F0 92 24 18 02 FE E8 DC 6E E0 10 0A 05 00 00 FA F6 F3
					39 00 00 40 00 00 13 81 F0 5C 24 16 02 FE EA DC A4 E0 0A 09 05 00 00 FE FB F0
					39 00 00 40 00 00 13 82 F0 48 24 11 02 FE EF DC B8 E0 0E 09 05 00 00 FF F7 F4
					39 00 00 40 00 00 13 83 F0 44 2C 10 02 FE F0 D4 BC E0 13 0D 05 00 00 FF FA F8
					39 00 00 40 00 00 13 86 F0 92 24 18 02 FE E8 DC 6E E0 10 0A 05 00 00 FA F6 F3
					39 00 00 40 00 00 13 87 F0 5C 24 16 02 FE EA DC A4 E0 0A 09 05 00 00 FE FB F0
					39 00 00 40 00 00 13 88 F0 48 24 11 02 FE EF DC B8 E0 0E 09 05 00 00 FF F7 F4
					39 00 00 40 00 00 13 89 F0 44 2C 10 02 FE F0 D4 BC E0 13 0D 05 00 00 FF FA F8
					15 00 00 40 00 00 02 D0 80
					39 00 00 00 01 00 04 FF 5A A5 00
					// te shift on
					39 00 00 40 00 00 04 FF 5A A5 02
					39 00 00 40 00 00 03 AB AF 82
					// ddic corner Hole
					39 00 00 40 00 00 04 FF 5A A5 13
					39 00 00 40 00 00 02 F9 4C //HOLE OFF
					39 00 00 40 00 00 04 FF 5A A5 17
					15 00 00 40 00 00 02 A0 0E //RCN OFF
					// pps table
					39 00 00 40 00 00 04 FF 5A A5 07
					15 00 00 40 00 00 02 8A 01
					39 00 00 40 00 00 03 8B 21 E0
					39 00 00 40 00 00 64 80 00 00 00 00 00 12 00 00 AB 30 80 0A D4 04 F8 00 16 02 7C 02 7C 02 00 02 59 00 20 02 2E 00 08 00 0D 04 F4 03 ED 18 00 10 F0 07 10 20 00 06 0F 0F 33 0E 1C 2A 38 46 54 62 69 70 77 79 7B 7D 7E 02 02 22 00 2A 40 2A BE 3A FC 3A FA 3A F8 3B 38 3B 78 3B B6 4B B6 4B F4 4B F4 6C 34 84 74 00 00 00 00 00 00
					39 00 00 40 00 00 64 81 00 00 00 00 00 12 00 00 AB 21 00 0A D4 04 F8 00 16 02 7C 02 7C 01 55 01 D7 00 0A 01 2D 00 35 00 0D 04 F4 16 3B 08 00 0C 00 07 10 20 00 06 0F 0F 33 0E 1C 2A 38 46 54 62 69 70 77 79 7B 7D 7E 00 82 11 40 19 C0 22 3E 32 7C 3A BA 3A F8 3B 38 3B 38 3B 76 4B 76 4B 74 4B 74 5B B4 73 F4 01 00 00 00 00 00
					39 00 00 40 00 00 04 FF 5A A5 07
					15 00 00 40 00 00 02 91 00         //Ycrcb
					39 00 00 40 00 00 04 FF 5A A5 14
					15 00 00 40 00 00 02 82 01       //SPR IN AP ON
					39 00 00 40 00 00 04 FF 5A A5 14
					15 00 00 40 00 00 02 80 00      //DDIC SPR OFF
					39 00 00 40 00 00 04 FF 5A A5 00
					39 00 00 40 00 00 04 FF 5A A5 06
					15 00 00 40 00 00 02 A0 00 //ESD fixed
					15 00 00 40 00 00 02 C6 01 //1bit ESD check
					39 00 00 40 00 00 04 FF 5A A5 08
					15 00 00 40 00 00 02 D2 05
					15 00 00 40 00 00 02 D3 01
					15 00 00 40 00 00 02 E0 22 // crc reset
					39 00 00 40 00 00 09 ED FF FF FF FF FF FF 45 FF
					39 00 00 40 00 00 09 EE FF FD FF FD F9 FA BE 76
					// osc fixed Auto trim TE
					39 00 00 40 00 00 04 FF 5A A5 22
					39 00 00 40 00 00 08 D8 00 FF 11 10 3C 18 18
					39 00 00 40 00 00 08 D9 00 BE 11 10 3C 12 12
					39 00 00 40 00 00 0A DC 84 94 BB 00 20 C4 A1 CC 10
					15 00 00 40 00 00 02 DD 01
					15 00 00 40 00 00 02 DE F1
					15 00 00 40 00 00 02 DF 80
					39 00 00 40 00 00 07 E0 02 00 5F 21 00 28
					39 00 00 40 00 00 04 FF 5A A5 00
					15 00 00 40 00 00 02 7D 01
					39 00 00 40 00 00 04 FF 5A A5 00
					15 00 00 40 00 00 02 5E 01
					15 00 00 40 00 00 02 60 02
					15 00 00 40 00 00 02 61 07
					15 00 00 40 00 00 02 6D 01
					15 00 00 40 00 00 02 35 00
					15 00 00 40 00 00 02 53 20
					// timing switch
					39 00 00 40 00 00 04 FF 5A A5 00
					15 00 00 40 00 00 02 60 02
					15 00 00 40 00 00 02 7D 01
					39 00 00 40 00 00 04 FF 5A A5 2D
					39 00 00 40 00 00 03 85 00 00
					// odc on
					39 00 00 40 00 00 04 FF 5A A5 49
					15 00 00 40 00 00 02 E0 01
					// dvdd sleep in
					39 00 00 40 00 00 04 FF 5A A5 1F
					39 00 00 40 00 00 05 96 15 30 03 01
					39 00 00 40 00 00 19 83 20 23 21 1E 1F 00 00 00 1E 1F 00 00 20 1F 20 23 20 00 00 00 00 00 00 00
					39 00 00 40 00 00 19 8F 0F 06 78 0E 11 00 00 00 0E 11 00 00 00 10 02 06 06 00 00 00 00 00 00 00
					39 00 00 40 00 00 04 FF 5A A5 00
					// pull dowm pmic
					39 00 00 40 00 00 04 FF 5A A5 1C
					39 00 00 40 00 00 16 E1 10 80 9A 65 59 54 69 95 56 6A 55 99 9A 55 55 25 58 55 66 A2 00
					39 00 00 40 00 00 04 FF 5A A5 05
					15 00 00 40 00 00 02 83 01
					// LGOCB change to 30
					39 00 00 40 00 00 04 FF 5A A5 53
					39 00 00 40 00 00 1F A2 10 10 10 10 10 10 10 10 30 30 10 10 10 10 10 10 10 10 30 30 10 10 10 10 10 10 10 10 30 30
					39 00 00 00 00 00 04 FF 5A A5 00
					//Light On
					39 00 00 00 78 00 01 11 // Sleep out
					39 00 00 40 00 00 04 FF 5A A5 00
					39 00 00 00 00 00 01 29 // Display out
				];
				oplus,dsi-aod-off-command = [
					39 00 00 00 00 00 04 FF 5A A5 00
					39 00 00 00 00 00 02 38 00
					39 00 00 00 00 00 05 51 00 00 00 00
					39 00 00 00 00 00 04 FF 5A A5 51
					39 00 00 00 00 00 07 A6 C7 C3 C3 C3 22 22
					39 00 00 00 00 00 04 FF 5A A5 52
					39 00 00 00 00 00 07 86 46 46 46 46 00 00
					39 00 00 00 00 00 04 FF 5A A5 02
					39 00 00 00 00 00 03 AB AF 82
				];
				oplus,dsi-ultra-low-power-aod-on-command = [
					39 00 00 00 00 00 04 FF 5A A5 2D
					39 00 00 00 00 00 03 8A 02 00
					39 00 00 00 00 00 04 FF 5A A5 00
				];
				oplus,dsi-ultra-low-power-aod-off-command = [
					39 00 00 00 00 00 04 FF 5A A5 2D
					39 00 00 00 00 00 03 8A 00 00
					39 00 00 00 00 00 04 FF 5A A5 00
				];
				oplus,dsi-hbm-on-command = [
					39 00 00 00 00 00 03 51 0E 7A
				];
				oplus,dsi-hbm-off-command = [
					39 00 00 00 00 00 03 51 0D BB
				];
				oplus,dsi-pwm-switch-1to3pul-command = [
				];
				oplus,dsi-pwm-switch-3to1pul-command = [
				];
				oplus,dsi-adfr-min-fps-90hz-command = [
					39 00 00 40 00 00 04 FF 5A A5 2D
					39 00 00 40 00 00 03 85 00 00
					39 00 00 00 00 00 04 FF 5A A5 00
				];
				oplus,dsi-adfr-min-fps-30hz-command = [
					39 00 00 40 00 00 04 FF 5A A5 2D
					39 00 00 40 00 00 03 85 02 00
					39 00 00 00 00 00 04 FF 5A A5 00
				];
				oplus,dsi-adfr-min-fps-10hz-command = [
					39 00 00 40 00 00 04 FF 5A A5 2D
					39 00 00 40 00 00 03 85 08 00
					39 00 00 00 00 00 04 FF 5A A5 00
				];
				oplus,dsi-adfr-min-fps-1hz-command = [
					39 00 00 40 00 00 04 FF 5A A5 2D
					39 00 00 40 00 00 03 85 59 00
					39 00 00 00 00 00 04 FF 5A A5 00
				];
				oplus,dsi-timing-switch-command-state = "dsi_hs_mode";
				oplus,dsi-timing-switch-1pulse-command-state = "dsi_hs_mode";
				oplus,dsi-on-command-state = "dsi_lp_mode";
				oplus,dsi-aod-off-command-state = "dsi_ls_mode";
				oplus,dsi-ultra-low-power-aod-on-command-state = "dsi_ls_mode";
				oplus,dsi-ultra-low-power-aod-off-command-state = "dsi_ls_mode";
				oplus,dsi-hbm-on-command-state = "dsi_hs_mode";
				oplus,dsi-hbm-off-command-state = "dsi_hs_mode";
				oplus,dsi-pwm-switch-1to3pul-command-state = "dsi_hs_mode";
				oplus,dsi-pwm-switch-3to1pul-command-state = "dsi_hs_mode";
				oplus,dsi-adfr-min-fps-90hz-command-state = "dsi_hs_mode";
				oplus,dsi-adfr-min-fps-30hz-command-state = "dsi_hs_mode";
				oplus,dsi-adfr-min-fps-10hz-command-state = "dsi_hs_mode";
				oplus,dsi-adfr-min-fps-1hz-command-state = "dsi_hs_mode";
				oplus,dsc-params-entries = <&dsc_params>;
				oplus,spr-params-entries = <&spr_params>;
				oplus,dyn-fps {
					switch_en = <1>;
					vact_timing_fps = <90>;
					apollo_limit_superior_us = <7880>;
					apollo_limit_inferior_us = <10000>;
					apollo_transfer_time_us = <8560>;
				};
				oplus,display-mode {
					display-mode@0 {
						hdisplay = <1272>;
						vdisplay = <2772>;
						fhd-hfp = <2>;
						fhd-hsa = <26>;
						fhd-hbp = <36>;
						fhd-vfp = <100>;
						fhd-vsa = <8>;
						fhd-vbp = <76>;
						hskew = <STANDARD_ADFR>;
					};
					display-mode@1 {
						hdisplay = <1080>;
						vdisplay = <2354>;
						fhd-hfp = <2>;
						fhd-hsa = <26>;
						fhd-hbp = <36>;
						fhd-vfp = <100>;
						fhd-vsa = <8>;
						fhd-vbp = <76>;
						hskew = <STANDARD_ADFR>;
					};
				};
			};
			timing@sa_fhd_60 {
				cell-index = <2>;
				mtk,skip_vblank = <1>;
				mtk,real_te_duration = <16667>;
				oplus,dsi-panel-framerate = <60>;
				oplus,dsi-panel-pllclk = <556>;
				oplus,cmd-null-pkt-en = <1>;
				oplus,cmd-null-pkt-len = <280>;
				/* OPLUS_FEATURE_DISPLAY_ONSCREENFINGERPRINT */
				oplus,ofp_need_keep_apart_backlight;
				oplus,ofp-hbm-on-delay = <0>;
				oplus,ofp-pre-hbm-off-delay = <2>;
				oplus,ofp-hbm-off-delay = <0>;
				oplus,ofp-need-to-sync-data-in-aod-unlocking;
				oplus,ofp-aod-off-insert-black = <1>;
				oplus,ofp-aod-off-black-frame-total-time = <42>;
				#include "panel-ac283-p-7-a0020-dsi-cmd-common.dtsi"
				oplus,dsi-timing-switch-command = [
					39 00 00 40 00 00 04 FF 5A A5 00
					15 00 00 40 00 00 02 60 00
					15 00 00 40 00 00 02 7D 00
					39 00 00 40 00 00 04 FF 5A A5 2D
					39 00 00 40 00 00 03 83 01 00
					15 00 00 00 00 00 02 F2 01
				];
				oplus,dsi-timing-switch-1pulse-command = [
				];
				oplus,dsi-on-command = [
					39 00 00 40 00 00 04 FF 5A A5 08
					15 00 00 40 00 00 02 C8 62 //OTP don’t reload
					39 00 00 40 00 00 04 FF 5A A5 21
					15 00 00 40 00 00 02 A4 38 //Flash reload
					39 00 00 40 00 00 04 FF 5A A5 23
					15 00 00 40 00 00 02 85 15 //BC reload by OTP
					39 00 00 40 00 00 04 FF 5A A5 01
					15 00 00 40 00 00 02 FB 08 //Multi TE
					// odc impro
					39 00 00 40 00 00 04 FF 5A A5 49
					39 00 00 40 00 00 0C 80 00 08 0C 1C 3C 7C 8C CC 0C 00 01
					39 00 00 40 00 00 11 81 00 00 9E 00 E5 00 6C 01 41 02 A6 03 8B 05 DD 06
					39 00 00 40 00 00 13 82 00 00 9E 00 E5 00 6C 01 41 02 A6 03 8B 05 DD 06 00 00
					15 00 00 40 00 00 02 83 07
					15 00 00 40 00 00 02 84 14
					39 00 00 40 00 00 04 85 80 00 02
					39 00 00 40 00 00 04 86 80 00 02
					39 00 00 40 00 00 04 A0 40 40 40
					39 00 00 40 00 00 04 A1 40 40 40
					39 00 00 40 00 00 04 A2 40 40 40
					15 00 00 40 00 00 02 A6 3F
					15 00 00 40 00 00 02 A7 07
					15 00 00 40 00 00 02 AD 01
					15 00 00 40 00 00 02 AE 08
					15 00 00 40 00 00 02 AF 08
					15 00 00 40 00 00 02 D9 02
					15 00 00 40 00 00 02 DA F7
					15 00 00 40 00 00 02 DB 9C
					15 00 00 40 00 00 02 DC 03
					15 00 00 40 00 00 02 DF 06
					15 00 00 40 00 00 02 E0 01
					39 00 00 40 00 00 04 FF 5A A5 5A
					39 00 00 40 00 00 04 80 00 00 00
					39 00 00 40 00 00 04 81 00 00 00
					39 00 00 40 00 00 04 82 00 00 00
					39 00 00 40 00 00 04 83 10 10 10
					39 00 00 40 00 00 04 84 00 00 00
					39 00 00 40 00 00 04 85 00 00 00
					39 00 00 40 00 00 04 86 48 02 30
					39 00 00 40 00 00 04 87 08 02 04
					39 00 00 40 00 00 04 88 08 02 04
					39 00 00 40 00 00 04 89 08 02 04
					39 00 00 40 00 00 04 8A 30 00 10
					39 00 00 40 00 00 04 8B 10 10 10
					39 00 00 40 00 00 04 8C 1A 1E 16
					39 00 00 40 00 00 04 8D 10 06 04
					39 00 00 40 00 00 04 8E 0B 06 0E
					39 00 00 40 00 00 04 8F 28 F9 0D
					39 00 00 40 00 00 04 90 12 10 10
					39 00 00 40 00 00 04 91 1D 12 15
					39 00 00 40 00 00 04 92 10 05 18
					39 00 00 40 00 00 04 93 08 FF 10
					39 00 00 40 00 00 04 94 02 FF 02
					39 00 00 40 00 00 04 95 20 0D 10
					39 00 00 40 00 00 04 96 0A 0D 0D
					39 00 00 40 00 00 04 97 0A 0D 0D
					39 00 00 40 00 00 04 98 12 14 18
					39 00 00 40 00 00 04 99 14 0E 1E
					39 00 00 40 00 00 04 9A 0A 06 0E
					39 00 00 40 00 00 04 9B 02 02 02
					39 00 00 40 00 00 04 9C 15 10 10
					39 00 00 40 00 00 04 9D 12 14 2E
					39 00 00 40 00 00 04 9E 10 26 20
					39 00 00 40 00 00 04 9F 1D 14 20
					39 00 00 40 00 00 04 A0 14 0A 1A
					39 00 00 40 00 00 04 A1 14 0A 10
					39 00 00 40 00 00 04 A2 12 08 12
					39 00 00 40 00 00 04 A3 02 02 02
					39 00 00 40 00 00 04 A4 00 00 00
					39 00 00 40 00 00 04 A5 06 F6 F5
					39 00 00 40 00 00 04 A6 00 00 00
					39 00 00 40 00 00 04 A7 02 00 00
					39 00 00 40 00 00 04 A8 00 02 00
					39 00 00 40 00 00 04 A9 00 02 00
					39 00 00 40 00 00 04 AA 08 F5 F0
					39 00 00 40 00 00 04 AB 06 06 0A
					39 00 00 40 00 00 04 AC 08 07 06
					39 00 00 40 00 00 04 AD 02 02 04
					39 00 00 40 00 00 04 AE 12 14 12
					39 00 00 40 00 00 04 AF 18 16 16
					39 00 00 40 00 00 04 B0 16 16 14
					39 00 00 40 00 00 04 B1 04 02 10
					39 00 00 40 00 00 04 B2 02 02 02
					39 00 00 40 00 00 04 B3 20 1A 2C
					39 00 00 40 00 00 04 B4 1C 16 1A
					39 00 00 40 00 00 04 B5 12 10 12
					39 00 00 40 00 00 04 B6 06 02 14
					39 00 00 40 00 00 04 B7 F6 04 02
					39 00 00 40 00 00 04 B8 F6 04 02
					39 00 00 40 00 00 04 B9 06 0D 0D
					39 00 00 40 00 00 04 BA 12 10 13
					39 00 00 40 00 00 04 BB 12 16 16
					39 00 00 40 00 00 04 BC 12 10 16
					39 00 00 40 00 00 04 BD 12 0E 12
					39 00 00 40 00 00 04 BE F6 06 02
					39 00 00 40 00 00 04 BF F6 06 02
					39 00 00 40 00 00 04 C0 12 12 12
					39 00 00 40 00 00 04 C1 12 16 10
					39 00 00 40 00 00 04 C2 12 16 1C
					39 00 00 40 00 00 04 C3 12 10 1C
					39 00 00 40 00 00 04 C4 18 18 1C
					39 00 00 40 00 00 04 C5 12 0E 16
					39 00 00 40 00 00 04 C6 16 1A 12
					39 00 00 40 00 00 04 C7 02 02 02
					39 00 00 40 00 00 04 C8 00 00 00
					39 00 00 40 00 00 04 C9 10 FC 0A
					39 00 00 40 00 00 04 CA 00 00 00
					39 00 00 40 00 00 04 CB 10 F6 0A
					39 00 00 40 00 00 04 CC 0A 08 00
					39 00 00 40 00 00 04 CD 08 06 00
					39 00 00 40 00 00 04 CE 0D 00 0A
					39 00 00 40 00 00 04 CF 04 04 04
					39 00 00 40 00 00 04 D0 04 06 06
					39 00 00 40 00 00 04 D1 02 04 04
					39 00 00 40 00 00 04 D2 16 16 14
					39 00 00 40 00 00 04 D3 16 14 14
					39 00 00 40 00 00 04 D4 14 14 12
					39 00 00 40 00 00 04 D5 10 10 10
					39 00 00 40 00 00 04 D6 02 02 02
					39 00 00 40 00 00 04 D7 12 18 16
					39 00 00 40 00 00 04 D8 12 16 12
					39 00 00 40 00 00 04 D9 10 16 12
					39 00 00 40 00 00 04 DA 0D 0A 0D
					39 00 00 40 00 00 04 DB F4 04 04
					39 00 00 40 00 00 04 DC F4 04 04
					39 00 00 40 00 00 04 DD 0D 12 10
					39 00 00 40 00 00 04 DE 0D 10 12
					39 00 00 40 00 00 04 DF 08 10 10
					39 00 00 40 00 00 04 E0 0D 20 18
					39 00 00 40 00 00 04 E1 08 14 10
					39 00 00 40 00 00 04 E2 F4 04 04
					39 00 00 40 00 00 04 E3 F4 04 04
					39 00 00 40 00 00 04 E4 0D 16 14
					39 00 00 40 00 00 04 E5 0D 12 12
					39 00 00 40 00 00 04 E6 0D 10 12
					39 00 00 40 00 00 04 E7 0D 10 12
					39 00 00 40 00 00 04 E8 0D 12 14
					39 00 00 40 00 00 04 E9 0A 10 10
					39 00 00 40 00 00 04 EA 06 10 0A
					39 00 00 40 00 00 04 EB 02 04 02
					39 00 00 40 00 00 04 FF 5A A5 5B
					39 00 00 40 00 00 04 80 00 00 00
					39 00 00 40 00 00 04 81 0D FC 02
					39 00 00 40 00 00 04 82 04 02 04
					39 00 00 40 00 00 04 83 0D 00 02
					39 00 00 40 00 00 04 84 04 04 03
					39 00 00 40 00 00 04 85 04 04 03
					39 00 00 40 00 00 04 86 03 00 01
					39 00 00 40 00 00 04 87 06 05 06
					39 00 00 40 00 00 04 88 05 03 06
					39 00 00 40 00 00 04 89 02 03 06
					39 00 00 40 00 00 04 8A 12 1A 14
					39 00 00 40 00 00 04 8B 14 18 14
					39 00 00 40 00 00 04 8C 14 18 14
					39 00 00 40 00 00 04 8D 10 12 0E
					39 00 00 40 00 00 04 8E 08 0A 08
					39 00 00 40 00 00 04 8F 10 34 2C
					39 00 00 40 00 00 04 90 10 1E 1A
					39 00 00 40 00 00 04 91 10 1E 18
					39 00 00 40 00 00 04 92 10 18 14
					39 00 00 40 00 00 04 93 F0 06 06
					39 00 00 40 00 00 04 94 F0 06 06
					39 00 00 40 00 00 04 95 06 16 16
					39 00 00 40 00 00 04 96 10 18 10
					39 00 00 40 00 00 04 97 12 16 16
					39 00 00 40 00 00 04 98 12 1E 16
					39 00 00 40 00 00 04 99 0D 14 18
					39 00 00 40 00 00 04 9A F0 06 06
					39 00 00 40 00 00 04 9B F0 06 06
					39 00 00 40 00 00 04 9C 14 18 14
					39 00 00 40 00 00 04 9D 16 16 12
					39 00 00 40 00 00 04 9E 0D 16 1E
					39 00 00 40 00 00 04 9F 0D 12 12
					39 00 00 40 00 00 04 A0 0D 16 18
					39 00 00 40 00 00 04 A1 18 16 16
					39 00 00 40 00 00 04 A2 02 02 02
					39 00 00 40 00 00 04 A3 02 02 02
					39 00 00 40 00 00 04 A4 05 00 04
					39 00 00 40 00 00 04 A5 08 03 02
					39 00 00 40 00 00 04 A6 02 02 00
					39 00 00 40 00 00 04 A7 06 03 02
					39 00 00 40 00 00 04 A8 02 02 00
					39 00 00 40 00 00 04 A9 02 02 00
					39 00 00 40 00 00 04 AA 06 06 06
					39 00 00 40 00 00 04 AB 06 06 04
					39 00 00 40 00 00 04 AC 04 06 04
					39 00 00 40 00 00 04 AD 02 02 02
					39 00 00 40 00 00 04 AE 12 12 14
					39 00 00 40 00 00 04 AF 14 16 14
					39 00 00 40 00 00 04 B0 12 14 12
					39 00 00 40 00 00 04 B1 04 02 0E
					39 00 00 40 00 00 04 B2 04 02 08
					39 00 00 40 00 00 04 B3 20 28 20
					39 00 00 40 00 00 04 B4 0D 16 12
					39 00 00 40 00 00 04 B5 0D 10 10
					39 00 00 40 00 00 04 B6 F6 02 02
					39 00 00 40 00 00 04 B7 F0 06 02
					39 00 00 40 00 00 04 B8 F0 06 02
					39 00 00 40 00 00 04 B9 0D 14 16
					39 00 00 40 00 00 04 BA 0F 12 16
					39 00 00 40 00 00 04 BB 14 16 12
					39 00 00 40 00 00 04 BC 04 08 08
					39 00 00 40 00 00 04 BD F6 02 10
					39 00 00 40 00 00 04 BE F0 06 02
					39 00 00 40 00 00 04 BF F0 06 02
					39 00 00 40 00 00 04 C0 10 16 12
					39 00 00 40 00 00 04 C1 14 16 18
					39 00 00 40 00 00 04 C2 16 14 10
					39 00 00 40 00 00 04 C3 10 12 16
					39 00 00 40 00 00 04 C4 02 0A 16
					39 00 00 40 00 00 04 C5 00 02 16
					39 00 00 40 00 00 04 C6 00 0A 14
					39 00 00 40 00 00 04 C7 02 02 02
					39 00 00 40 00 00 04 C8 06 00 06
					39 00 00 40 00 00 04 C9 05 02 02
					39 00 00 40 00 00 04 CA 00 00 00
					39 00 00 40 00 00 04 CB 04 04 03
					39 00 00 40 00 00 04 CC 02 02 02
					39 00 00 40 00 00 04 CD 00 00 00
					39 00 00 40 00 00 04 CE 0C 0C 0E
					39 00 00 40 00 00 04 CF 06 06 06
					39 00 00 40 00 00 04 D0 04 06 04
					39 00 00 40 00 00 04 D1 02 02 02
					39 00 00 40 00 00 04 D2 12 12 12
					39 00 00 40 00 00 04 D3 12 12 12
					39 00 00 40 00 00 04 D4 14 16 14
					39 00 00 40 00 00 04 D5 06 06 0A
					39 00 00 40 00 00 04 D6 02 02 06
					39 00 00 40 00 00 04 D7 1D 24 1E
					39 00 00 40 00 00 04 D8 16 1E 1A
					39 00 00 40 00 00 04 D9 12 1A 18
					39 00 00 40 00 00 04 DA 02 04 10
					39 00 00 40 00 00 04 DB FD 02 0A
					39 00 00 40 00 00 04 DC FD 00 00
					39 00 00 40 00 00 04 DD 12 18 1D
					39 00 00 40 00 00 04 DE 14 1B 1E
					39 00 00 40 00 00 04 DF 10 1A 1D
					39 00 00 40 00 00 04 E0 10 1A 14
					39 00 00 40 00 00 04 E1 02 0A 06
					39 00 00 40 00 00 04 E2 FD 02 02
					39 00 00 40 00 00 04 E3 FD 02 02
					39 00 00 40 00 00 04 E4 14 18 1C
					39 00 00 40 00 00 04 E5 10 1A 1A
					39 00 00 40 00 00 04 E6 1A 14 16
					39 00 00 40 00 00 04 E7 18 16 1C
					39 00 00 40 00 00 04 E8 14 10 10
					39 00 00 40 00 00 04 E9 0C 0E 12
					39 00 00 40 00 00 04 EA 14 12 10
					39 00 00 40 00 00 04 EB 02 02 02
					39 00 00 40 00 00 04 FF 5A A5 5C
					39 00 00 40 00 00 04 80 03 01 00
					39 00 00 40 00 00 04 81 04 02 02
					39 00 00 40 00 00 04 82 00 00 00
					39 00 00 40 00 00 04 83 01 03 02
					39 00 00 40 00 00 04 84 02 02 02
					39 00 00 40 00 00 04 85 00 00 00
					39 00 00 40 00 00 04 86 0E 10 0E
					39 00 00 40 00 00 04 87 06 06 06
					39 00 00 40 00 00 04 88 06 06 06
					39 00 00 40 00 00 04 89 02 02 02
					39 00 00 40 00 00 04 8A 16 16 14
					39 00 00 40 00 00 04 8B 16 18 14
					39 00 00 40 00 00 04 8C 14 16 12
					39 00 00 40 00 00 04 8D 0E 0E 0C
					39 00 00 40 00 00 04 8E 06 08 06
					39 00 00 40 00 00 04 8F 10 14 1C
					39 00 00 40 00 00 04 90 16 1E 18
					39 00 00 40 00 00 04 91 14 1A 16
					39 00 00 40 00 00 04 92 0D 12 10
					39 00 00 40 00 00 04 93 F2 06 04
					39 00 00 40 00 00 04 94 F2 06 04
					39 00 00 40 00 00 04 95 12 12 18
					39 00 00 40 00 00 04 96 12 10 1E
					39 00 00 40 00 00 04 97 12 18 1E
					39 00 00 40 00 00 04 98 12 1D 20
					39 00 00 40 00 00 04 99 12 1D 18
					39 00 00 40 00 00 04 9A F2 06 04
					39 00 00 40 00 00 04 9B F2 06 04
					39 00 00 40 00 00 04 9C 12 16 12
					39 00 00 40 00 00 04 9D 18 1E 12
					39 00 00 40 00 00 04 9E 14 1C 12
					39 00 00 40 00 00 04 9F 10 12 16
					39 00 00 40 00 00 04 A0 12 12 1C
					39 00 00 40 00 00 04 A1 12 12 0E
					39 00 00 40 00 00 04 A2 0E 10 0C
					39 00 00 40 00 00 04 A3 06 08 06
					39 00 00 40 00 00 04 A4 02 00 00
					39 00 00 40 00 00 04 A5 02 02 02
					39 00 00 40 00 00 04 A6 00 00 00
					39 00 00 40 00 00 04 A7 01 01 00
					39 00 00 40 00 00 04 A8 02 02 02
					39 00 00 40 00 00 04 A9 00 00 00
					39 00 00 40 00 00 04 AA 04 06 05
					39 00 00 40 00 00 04 AB 08 08 06
					39 00 00 40 00 00 04 AC 06 06 06
					39 00 00 40 00 00 04 AD 04 06 02
					39 00 00 40 00 00 04 AE 14 16 16
					39 00 00 40 00 00 04 AF 12 1A 14
					39 00 00 40 00 00 04 B0 14 16 12
					39 00 00 40 00 00 04 B1 04 04 0C
					39 00 00 40 00 00 04 B2 06 02 06
					39 00 00 40 00 00 04 B3 18 1A 1C
					39 00 00 40 00 00 04 B4 1A 1E 18
					39 00 00 40 00 00 04 B5 18 1A 14
					39 00 00 40 00 00 04 B6 06 04 0E
					39 00 00 40 00 00 04 B7 00 02 02
					39 00 00 40 00 00 04 B8 FE 00 00
					39 00 00 40 00 00 04 B9 0D 1D 1C
					39 00 00 40 00 00 04 BA 12 1D 1E
					39 00 00 40 00 00 04 BB 14 13 15
					39 00 00 40 00 00 04 BC 04 0C 0B
					39 00 00 40 00 00 04 BD 04 0C 0B
					39 00 00 40 00 00 04 BE FE 02 02
					39 00 00 40 00 00 04 BF FE 02 02
					39 00 00 40 00 00 04 C0 12 18 16
					39 00 00 40 00 00 04 C1 16 12 10
					39 00 00 40 00 00 04 C2 1C 16 1C
					39 00 00 40 00 00 04 C3 10 14 16
					39 00 00 40 00 00 04 C4 14 0A 1C
					39 00 00 40 00 00 04 C5 0E 08 10
					39 00 00 40 00 00 04 C6 0A 04 0A
					39 00 00 40 00 00 04 C7 00 00 00
					39 00 00 40 00 00 04 C8 04 04 04
					39 00 00 40 00 00 04 C9 0A 04 04
					39 00 00 40 00 00 04 CA 0A 04 04
					39 00 00 40 00 00 04 CB 0A 04 04
					39 00 00 40 00 00 04 CC 00 00 00
					39 00 00 40 00 00 04 CD 01 01 01
					39 00 00 40 00 00 04 CE 02 00 00
					39 00 00 40 00 00 04 CF 02 01 01
					39 00 00 00 00 00 04 FF 5A A5 00
					// ctb impro
					39 00 00 40 00 00 04 FF 5A A5 31
					39 00 00 40 00 00 0B 90 02 03 05 07 0A 02 03 05 07 0A
					39 00 00 40 00 00 19 8C 21 13 0C 0B 08 04 00 00 00 00 00 00 00 00 00 00 00 00 00 00 00 00 00 00
					39 00 00 40 00 00 1A 8D 16 0A 06 00 00 00 00 00 00 00 00 00 00 00 00 00 00 00 00 00 00 00 00 00 00
					39 00 00 40 00 00 09 8F 40 40 40 40 40 40 40 40
					15 00 00 40 00 00 02 D0 81
					39 00 00 40 00 00 13 80 F0 92 24 18 02 FE E8 DC 6E E0 10 0A 05 00 00 FA F6 F3
					39 00 00 40 00 00 13 81 F0 5C 24 16 02 FE EA DC A4 E0 0A 09 05 00 00 FE FB F0
					39 00 00 40 00 00 13 82 F0 48 24 11 02 FE EF DC B8 E0 0E 09 05 00 00 FF F7 F4
					39 00 00 40 00 00 13 83 F0 44 2C 10 02 FE F0 D4 BC E0 13 0D 05 00 00 FF FA F8
					39 00 00 40 00 00 13 86 F0 92 24 18 02 FE E8 DC 6E E0 10 0A 05 00 00 FA F6 F3
					39 00 00 40 00 00 13 87 F0 5C 24 16 02 FE EA DC A4 E0 0A 09 05 00 00 FE FB F0
					39 00 00 40 00 00 13 88 F0 48 24 11 02 FE EF DC B8 E0 0E 09 05 00 00 FF F7 F4
					39 00 00 40 00 00 13 89 F0 44 2C 10 02 FE F0 D4 BC E0 13 0D 05 00 00 FF FA F8
					15 00 00 40 00 00 02 D0 80
					39 00 00 00 01 00 04 FF 5A A5 00
					// te shift on
					39 00 00 40 00 00 04 FF 5A A5 02
					39 00 00 40 00 00 03 AB AF 82
					// ddic corner Hole
					39 00 00 40 00 00 04 FF 5A A5 13
					39 00 00 40 00 00 02 F9 4C //HOLE OFF
					39 00 00 40 00 00 04 FF 5A A5 17
					15 00 00 40 00 00 02 A0 0E //RCN OFF
					// pps table
					39 00 00 40 00 00 04 FF 5A A5 07
					15 00 00 40 00 00 02 8A 01
					39 00 00 40 00 00 03 8B 21 E0
					39 00 00 40 00 00 64 80 00 00 00 00 00 12 00 00 AB 30 80 0A D4 04 F8 00 16 02 7C 02 7C 02 00 02 59 00 20 02 2E 00 08 00 0D 04 F4 03 ED 18 00 10 F0 07 10 20 00 06 0F 0F 33 0E 1C 2A 38 46 54 62 69 70 77 79 7B 7D 7E 02 02 22 00 2A 40 2A BE 3A FC 3A FA 3A F8 3B 38 3B 78 3B B6 4B B6 4B F4 4B F4 6C 34 84 74 00 00 00 00 00 00
					39 00 00 40 00 00 64 81 00 00 00 00 00 12 00 00 AB 21 00 0A D4 04 F8 00 16 02 7C 02 7C 01 55 01 D7 00 0A 01 2D 00 35 00 0D 04 F4 16 3B 08 00 0C 00 07 10 20 00 06 0F 0F 33 0E 1C 2A 38 46 54 62 69 70 77 79 7B 7D 7E 00 82 11 40 19 C0 22 3E 32 7C 3A BA 3A F8 3B 38 3B 38 3B 76 4B 76 4B 74 4B 74 5B B4 73 F4 01 00 00 00 00 00
					39 00 00 40 00 00 04 FF 5A A5 07
					15 00 00 40 00 00 02 91 00         //Ycrcb
					39 00 00 40 00 00 04 FF 5A A5 14
					15 00 00 40 00 00 02 82 01       //SPR IN AP ON
					39 00 00 40 00 00 04 FF 5A A5 14
					15 00 00 40 00 00 02 80 00      //DDIC SPR OFF
					39 00 00 40 00 00 04 FF 5A A5 00
					39 00 00 40 00 00 04 FF 5A A5 06
					15 00 00 40 00 00 02 A0 00 //ESD fixed
					15 00 00 40 00 00 02 C6 01 //1bit ESD check
					39 00 00 40 00 00 04 FF 5A A5 08
					15 00 00 40 00 00 02 D2 05
					15 00 00 40 00 00 02 D3 01
					15 00 00 40 00 00 02 E0 22 // crc reset
					39 00 00 40 00 00 09 ED FF FF FF FF FF FF 45 FF
					39 00 00 40 00 00 09 EE FF FD FF FD F9 FA BE 76
					// osc fixed Auto trim TE
					39 00 00 40 00 00 04 FF 5A A5 22
					39 00 00 40 00 00 08 D8 00 FF 11 10 3C 18 18
					39 00 00 40 00 00 08 D9 00 BE 11 10 3C 12 12
					39 00 00 40 00 00 0A DC 84 94 BB 00 20 C4 A1 CC 10
					15 00 00 40 00 00 02 DD 01
					15 00 00 40 00 00 02 DE F1
					15 00 00 40 00 00 02 DF 80
					39 00 00 40 00 00 07 E0 02 00 5F 21 00 28
					39 00 00 40 00 00 04 FF 5A A5 00
					15 00 00 40 00 00 02 7D 00
					39 00 00 40 00 00 04 FF 5A A5 00
					15 00 00 40 00 00 02 5E 01
					15 00 00 40 00 00 02 60 00
					15 00 00 40 00 00 02 61 07
					15 00 00 40 00 00 02 6D 01
					15 00 00 40 00 00 02 35 00
					15 00 00 40 00 00 02 53 20
					// timing switch
					39 00 00 40 00 00 04 FF 5A A5 00
					15 00 00 40 00 00 02 60 00
					15 00 00 40 00 00 02 7D 00
					39 00 00 40 00 00 04 FF 5A A5 2D
					39 00 00 40 00 00 03 83 01 00
					15 00 00 40 00 00 02 F2 01
					// odc on
					39 00 00 40 00 00 04 FF 5A A5 49
					15 00 00 40 00 00 02 E0 01
					// dvdd sleep in
					39 00 00 40 00 00 04 FF 5A A5 1F
					39 00 00 40 00 00 05 96 15 30 03 01
					39 00 00 40 00 00 19 83 20 23 21 1E 1F 00 00 00 1E 1F 00 00 20 1F 20 23 20 00 00 00 00 00 00 00
					39 00 00 40 00 00 19 8F 0F 06 78 0E 11 00 00 00 0E 11 00 00 00 10 02 06 06 00 00 00 00 00 00 00
					39 00 00 40 00 00 04 FF 5A A5 00
					// pull dowm pmic
					39 00 00 40 00 00 04 FF 5A A5 1C
					39 00 00 40 00 00 16 E1 10 80 9A 65 59 54 69 95 56 6A 55 99 9A 55 55 25 58 55 66 A2 00
					39 00 00 40 00 00 04 FF 5A A5 05
					15 00 00 40 00 00 02 83 01
					// LGOCB change to 30
					39 00 00 40 00 00 04 FF 5A A5 53
					39 00 00 40 00 00 1F A2 10 10 10 10 10 10 10 10 30 30 10 10 10 10 10 10 10 10 30 30 10 10 10 10 10 10 10 10 30 30
					39 00 00 00 00 00 04 FF 5A A5 00
					//Light On
					39 00 00 00 78 00 01 11 // Sleep out
					39 00 00 40 00 00 04 FF 5A A5 00
					39 00 00 00 00 00 01 29 // Display out
				];
				oplus,dsi-aod-off-command = [
					39 00 00 00 00 00 04 FF 5A A5 00
					39 00 00 00 00 00 02 38 00
					39 00 00 00 00 00 05 51 00 00 00 00
					39 00 00 00 00 00 04 FF 5A A5 51
					39 00 00 00 00 00 07 A6 C7 C3 C3 C3 22 22
					39 00 00 00 00 00 04 FF 5A A5 52
					39 00 00 00 00 00 07 86 46 46 46 46 00 00
					39 00 00 00 00 00 04 FF 5A A5 02
					39 00 00 00 00 00 03 AB AF 82
				];
				oplus,dsi-ultra-low-power-aod-on-command = [
					39 00 00 00 00 00 04 FF 5A A5 2D
					39 00 00 00 00 00 03 8A 02 00
					39 00 00 00 00 00 04 FF 5A A5 00
				];
				oplus,dsi-ultra-low-power-aod-off-command = [
					39 00 00 00 00 00 04 FF 5A A5 2D
					39 00 00 00 00 00 03 8A 00 00
					39 00 00 00 00 00 04 FF 5A A5 00
				];
				oplus,dsi-hbm-on-command = [
					39 00 00 00 00 00 03 51 0E 7A
				];
				oplus,dsi-hbm-off-command = [
					39 00 00 00 00 00 03 51 0D BB
				];
				oplus,dsi-pwm-switch-1to3pul-command = [
				];
				oplus,dsi-pwm-switch-3to1pul-command = [
				];
				oplus,dsi-adfr-min-fps-60hz-command = [
					39 00 00 40 00 00 04 FF 5A A5 2D
					39 00 00 40 00 00 03 83 01 00
					39 00 00 00 00 00 04 FF 5A A5 00
				];
				oplus,dsi-adfr-min-fps-30hz-command = [
					39 00 00 40 00 00 04 FF 5A A5 2D
					39 00 00 40 00 00 03 83 03 00
					39 00 00 00 00 00 04 FF 5A A5 00
				];
				oplus,dsi-adfr-min-fps-10hz-command = [
					39 00 00 40 00 00 04 FF 5A A5 2D
					39 00 00 40 00 00 03 83 0B 00
					39 00 00 00 00 00 04 FF 5A A5 00
				];
				oplus,dsi-adfr-min-fps-1hz-command = [
					39 00 00 40 00 00 04 FF 5A A5 2D
					39 00 00 40 00 00 03 83 77 00
					39 00 00 00 00 00 04 FF 5A A5 00
				];
				oplus,dsi-timing-switch-command-state = "dsi_hs_mode";
				oplus,dsi-timing-switch-1pulse-command-state = "dsi_hs_mode";
				oplus,dsi-on-command-state = "dsi_lp_mode";
				oplus,dsi-aod-off-command-state = "dsi_ls_mode";
				oplus,dsi-ultra-low-power-aod-on-command-state = "dsi_ls_mode";
				oplus,dsi-ultra-low-power-aod-off-command-state = "dsi_ls_mode";
				oplus,dsi-hbm-on-command-state = "dsi_hs_mode";
				oplus,dsi-hbm-off-command-state = "dsi_hs_mode";
				oplus,dsi-pwm-switch-1to3pul-command-state = "dsi_hs_mode";
				oplus,dsi-pwm-switch-3to1pul-command-state = "dsi_hs_mode";
				oplus,dsi-adfr-min-fps-60hz-command-state = "dsi_hs_mode";
				oplus,dsi-adfr-min-fps-30hz-command-state = "dsi_hs_mode";
				oplus,dsi-adfr-min-fps-10hz-command-state = "dsi_hs_mode";
				oplus,dsi-adfr-min-fps-1hz-command-state = "dsi_hs_mode";
				oplus,dsc-params-entries = <&dsc_params>;
				oplus,spr-params-entries = <&spr_params>;
				oplus,dyn-fps {
					switch_en = <1>;
					vact_timing_fps = <60>;
					apollo_limit_superior_us = <11540>;
					apollo_limit_inferior_us = <15500>;
					apollo_transfer_time_us = <7800>;
				};
				oplus,display-mode {
					display-mode@0 {
						hdisplay = <1272>;
						vdisplay = <2772>;
						fhd-hfp = <2>;
						fhd-hsa = <26>;
						fhd-hbp = <36>;
						fhd-vfp = <100>;
						fhd-vsa = <8>;
						fhd-vbp = <76>;
						hskew = <STANDARD_MFR>;
					};
					display-mode@1 {
						hdisplay = <1080>;
						vdisplay = <2354>;
						fhd-hfp = <2>;
						fhd-hsa = <26>;
						fhd-hbp = <36>;
						fhd-vfp = <100>;
						fhd-vsa = <8>;
						fhd-vbp = <76>;
						hskew = <STANDARD_MFR>;
					};
				};
			};
			timing@oa_fhd_120 {
				cell-index = <3>;
				mtk,skip_vblank = <3>;
				mtk,real_te_duration = <2778>;
				oplus,dsi-panel-framerate = <120>;
				oplus,adfr-timing-type = <2>;
				oplus,dsi-panel-pllclk = <556>;
				oplus,cmd-null-pkt-en = <0>;
				oplus,cmd-null-pkt-len = <0>;
				/* OPLUS_FEATURE_DISPLAY_ONSCREENFINGERPRINT */
				oplus,ofp_need_keep_apart_backlight;
				oplus,ofp-hbm-on-delay = <0>;
				oplus,ofp-pre-hbm-off-delay = <2>;
				oplus,ofp-hbm-off-delay = <0>;
				oplus,ofp-need-to-sync-data-in-aod-unlocking;
				oplus,ofp-aod-off-insert-black = <1>;
				oplus,ofp-aod-off-black-frame-total-time = <42>;
				#include "panel-ac283-p-7-a0020-dsi-cmd-common.dtsi"
				oplus,dsi-timing-switch-command = [
					39 00 00 40 00 00 04 FF 5A A5 00
					15 00 00 40 00 00 02 60 00
					15 00 00 40 00 00 02 7D 00
					39 00 00 40 00 00 04 FF 5A A5 2D
					39 00 00 40 00 00 03 83 00 00
					15 00 00 00 00 00 02 F2 00
				];
				oplus,dsi-timing-switch-1pulse-command = [
				];
				oplus,dsi-on-command = [
					39 00 00 40 00 00 04 FF 5A A5 08
					15 00 00 40 00 00 02 C8 62 //OTP don’t reload
					39 00 00 40 00 00 04 FF 5A A5 21
					15 00 00 40 00 00 02 A4 38 //Flash reload
					39 00 00 40 00 00 04 FF 5A A5 23
					15 00 00 40 00 00 02 85 15 //BC reload by OTP
					39 00 00 40 00 00 04 FF 5A A5 01
					15 00 00 40 00 00 02 FB 08 //Multi TE
					// odc impro
					39 00 00 40 00 00 04 FF 5A A5 49
					39 00 00 40 00 00 0C 80 00 08 0C 1C 3C 7C 8C CC 0C 00 01
					39 00 00 40 00 00 11 81 00 00 9E 00 E5 00 6C 01 41 02 A6 03 8B 05 DD 06
					39 00 00 40 00 00 13 82 00 00 9E 00 E5 00 6C 01 41 02 A6 03 8B 05 DD 06 00 00
					15 00 00 40 00 00 02 83 07
					15 00 00 40 00 00 02 84 14
					39 00 00 40 00 00 04 85 80 00 02
					39 00 00 40 00 00 04 86 80 00 02
					39 00 00 40 00 00 04 A0 40 40 40
					39 00 00 40 00 00 04 A1 40 40 40
					39 00 00 40 00 00 04 A2 40 40 40
					15 00 00 40 00 00 02 A6 3F
					15 00 00 40 00 00 02 A7 07
					15 00 00 40 00 00 02 AD 01
					15 00 00 40 00 00 02 AE 08
					15 00 00 40 00 00 02 AF 08
					15 00 00 40 00 00 02 D9 02
					15 00 00 40 00 00 02 DA F7
					15 00 00 40 00 00 02 DB 9C
					15 00 00 40 00 00 02 DC 03
					15 00 00 40 00 00 02 DF 06
					15 00 00 40 00 00 02 E0 01
					39 00 00 40 00 00 04 FF 5A A5 5A
					39 00 00 40 00 00 04 80 00 00 00
					39 00 00 40 00 00 04 81 00 00 00
					39 00 00 40 00 00 04 82 00 00 00
					39 00 00 40 00 00 04 83 10 10 10
					39 00 00 40 00 00 04 84 00 00 00
					39 00 00 40 00 00 04 85 00 00 00
					39 00 00 40 00 00 04 86 48 02 30
					39 00 00 40 00 00 04 87 08 02 04
					39 00 00 40 00 00 04 88 08 02 04
					39 00 00 40 00 00 04 89 08 02 04
					39 00 00 40 00 00 04 8A 30 00 10
					39 00 00 40 00 00 04 8B 10 10 10
					39 00 00 40 00 00 04 8C 1A 1E 16
					39 00 00 40 00 00 04 8D 10 06 04
					39 00 00 40 00 00 04 8E 0B 06 0E
					39 00 00 40 00 00 04 8F 28 F9 0D
					39 00 00 40 00 00 04 90 12 10 10
					39 00 00 40 00 00 04 91 1D 12 15
					39 00 00 40 00 00 04 92 10 05 18
					39 00 00 40 00 00 04 93 08 FF 10
					39 00 00 40 00 00 04 94 02 FF 02
					39 00 00 40 00 00 04 95 20 0D 10
					39 00 00 40 00 00 04 96 0A 0D 0D
					39 00 00 40 00 00 04 97 0A 0D 0D
					39 00 00 40 00 00 04 98 12 14 18
					39 00 00 40 00 00 04 99 14 0E 1E
					39 00 00 40 00 00 04 9A 0A 06 0E
					39 00 00 40 00 00 04 9B 02 02 02
					39 00 00 40 00 00 04 9C 15 10 10
					39 00 00 40 00 00 04 9D 12 14 2E
					39 00 00 40 00 00 04 9E 10 26 20
					39 00 00 40 00 00 04 9F 1D 14 20
					39 00 00 40 00 00 04 A0 14 0A 1A
					39 00 00 40 00 00 04 A1 14 0A 10
					39 00 00 40 00 00 04 A2 12 08 12
					39 00 00 40 00 00 04 A3 02 02 02
					39 00 00 40 00 00 04 A4 00 00 00
					39 00 00 40 00 00 04 A5 06 F6 F5
					39 00 00 40 00 00 04 A6 00 00 00
					39 00 00 40 00 00 04 A7 02 00 00
					39 00 00 40 00 00 04 A8 00 02 00
					39 00 00 40 00 00 04 A9 00 02 00
					39 00 00 40 00 00 04 AA 08 F5 F0
					39 00 00 40 00 00 04 AB 06 06 0A
					39 00 00 40 00 00 04 AC 08 07 06
					39 00 00 40 00 00 04 AD 02 02 04
					39 00 00 40 00 00 04 AE 12 14 12
					39 00 00 40 00 00 04 AF 18 16 16
					39 00 00 40 00 00 04 B0 16 16 14
					39 00 00 40 00 00 04 B1 04 02 10
					39 00 00 40 00 00 04 B2 02 02 02
					39 00 00 40 00 00 04 B3 20 1A 2C
					39 00 00 40 00 00 04 B4 1C 16 1A
					39 00 00 40 00 00 04 B5 12 10 12
					39 00 00 40 00 00 04 B6 06 02 14
					39 00 00 40 00 00 04 B7 F6 04 02
					39 00 00 40 00 00 04 B8 F6 04 02
					39 00 00 40 00 00 04 B9 06 0D 0D
					39 00 00 40 00 00 04 BA 12 10 13
					39 00 00 40 00 00 04 BB 12 16 16
					39 00 00 40 00 00 04 BC 12 10 16
					39 00 00 40 00 00 04 BD 12 0E 12
					39 00 00 40 00 00 04 BE F6 06 02
					39 00 00 40 00 00 04 BF F6 06 02
					39 00 00 40 00 00 04 C0 12 12 12
					39 00 00 40 00 00 04 C1 12 16 10
					39 00 00 40 00 00 04 C2 12 16 1C
					39 00 00 40 00 00 04 C3 12 10 1C
					39 00 00 40 00 00 04 C4 18 18 1C
					39 00 00 40 00 00 04 C5 12 0E 16
					39 00 00 40 00 00 04 C6 16 1A 12
					39 00 00 40 00 00 04 C7 02 02 02
					39 00 00 40 00 00 04 C8 00 00 00
					39 00 00 40 00 00 04 C9 10 FC 0A
					39 00 00 40 00 00 04 CA 00 00 00
					39 00 00 40 00 00 04 CB 10 F6 0A
					39 00 00 40 00 00 04 CC 0A 08 00
					39 00 00 40 00 00 04 CD 08 06 00
					39 00 00 40 00 00 04 CE 0D 00 0A
					39 00 00 40 00 00 04 CF 04 04 04
					39 00 00 40 00 00 04 D0 04 06 06
					39 00 00 40 00 00 04 D1 02 04 04
					39 00 00 40 00 00 04 D2 16 16 14
					39 00 00 40 00 00 04 D3 16 14 14
					39 00 00 40 00 00 04 D4 14 14 12
					39 00 00 40 00 00 04 D5 10 10 10
					39 00 00 40 00 00 04 D6 02 02 02
					39 00 00 40 00 00 04 D7 12 18 16
					39 00 00 40 00 00 04 D8 12 16 12
					39 00 00 40 00 00 04 D9 10 16 12
					39 00 00 40 00 00 04 DA 0D 0A 0D
					39 00 00 40 00 00 04 DB F4 04 04
					39 00 00 40 00 00 04 DC F4 04 04
					39 00 00 40 00 00 04 DD 0D 12 10
					39 00 00 40 00 00 04 DE 0D 10 12
					39 00 00 40 00 00 04 DF 08 10 10
					39 00 00 40 00 00 04 E0 0D 20 18
					39 00 00 40 00 00 04 E1 08 14 10
					39 00 00 40 00 00 04 E2 F4 04 04
					39 00 00 40 00 00 04 E3 F4 04 04
					39 00 00 40 00 00 04 E4 0D 16 14
					39 00 00 40 00 00 04 E5 0D 12 12
					39 00 00 40 00 00 04 E6 0D 10 12
					39 00 00 40 00 00 04 E7 0D 10 12
					39 00 00 40 00 00 04 E8 0D 12 14
					39 00 00 40 00 00 04 E9 0A 10 10
					39 00 00 40 00 00 04 EA 06 10 0A
					39 00 00 40 00 00 04 EB 02 04 02
					39 00 00 40 00 00 04 FF 5A A5 5B
					39 00 00 40 00 00 04 80 00 00 00
					39 00 00 40 00 00 04 81 0D FC 02
					39 00 00 40 00 00 04 82 04 02 04
					39 00 00 40 00 00 04 83 0D 00 02
					39 00 00 40 00 00 04 84 04 04 03
					39 00 00 40 00 00 04 85 04 04 03
					39 00 00 40 00 00 04 86 03 00 01
					39 00 00 40 00 00 04 87 06 05 06
					39 00 00 40 00 00 04 88 05 03 06
					39 00 00 40 00 00 04 89 02 03 06
					39 00 00 40 00 00 04 8A 12 1A 14
					39 00 00 40 00 00 04 8B 14 18 14
					39 00 00 40 00 00 04 8C 14 18 14
					39 00 00 40 00 00 04 8D 10 12 0E
					39 00 00 40 00 00 04 8E 08 0A 08
					39 00 00 40 00 00 04 8F 10 34 2C
					39 00 00 40 00 00 04 90 10 1E 1A
					39 00 00 40 00 00 04 91 10 1E 18
					39 00 00 40 00 00 04 92 10 18 14
					39 00 00 40 00 00 04 93 F0 06 06
					39 00 00 40 00 00 04 94 F0 06 06
					39 00 00 40 00 00 04 95 06 16 16
					39 00 00 40 00 00 04 96 10 18 10
					39 00 00 40 00 00 04 97 12 16 16
					39 00 00 40 00 00 04 98 12 1E 16
					39 00 00 40 00 00 04 99 0D 14 18
					39 00 00 40 00 00 04 9A F0 06 06
					39 00 00 40 00 00 04 9B F0 06 06
					39 00 00 40 00 00 04 9C 14 18 14
					39 00 00 40 00 00 04 9D 16 16 12
					39 00 00 40 00 00 04 9E 0D 16 1E
					39 00 00 40 00 00 04 9F 0D 12 12
					39 00 00 40 00 00 04 A0 0D 16 18
					39 00 00 40 00 00 04 A1 18 16 16
					39 00 00 40 00 00 04 A2 02 02 02
					39 00 00 40 00 00 04 A3 02 02 02
					39 00 00 40 00 00 04 A4 05 00 04
					39 00 00 40 00 00 04 A5 08 03 02
					39 00 00 40 00 00 04 A6 02 02 00
					39 00 00 40 00 00 04 A7 06 03 02
					39 00 00 40 00 00 04 A8 02 02 00
					39 00 00 40 00 00 04 A9 02 02 00
					39 00 00 40 00 00 04 AA 06 06 06
					39 00 00 40 00 00 04 AB 06 06 04
					39 00 00 40 00 00 04 AC 04 06 04
					39 00 00 40 00 00 04 AD 02 02 02
					39 00 00 40 00 00 04 AE 12 12 14
					39 00 00 40 00 00 04 AF 14 16 14
					39 00 00 40 00 00 04 B0 12 14 12
					39 00 00 40 00 00 04 B1 04 02 0E
					39 00 00 40 00 00 04 B2 04 02 08
					39 00 00 40 00 00 04 B3 20 28 20
					39 00 00 40 00 00 04 B4 0D 16 12
					39 00 00 40 00 00 04 B5 0D 10 10
					39 00 00 40 00 00 04 B6 F6 02 02
					39 00 00 40 00 00 04 B7 F0 06 02
					39 00 00 40 00 00 04 B8 F0 06 02
					39 00 00 40 00 00 04 B9 0D 14 16
					39 00 00 40 00 00 04 BA 0F 12 16
					39 00 00 40 00 00 04 BB 14 16 12
					39 00 00 40 00 00 04 BC 04 08 08
					39 00 00 40 00 00 04 BD F6 02 10
					39 00 00 40 00 00 04 BE F0 06 02
					39 00 00 40 00 00 04 BF F0 06 02
					39 00 00 40 00 00 04 C0 10 16 12
					39 00 00 40 00 00 04 C1 14 16 18
					39 00 00 40 00 00 04 C2 16 14 10
					39 00 00 40 00 00 04 C3 10 12 16
					39 00 00 40 00 00 04 C4 02 0A 16
					39 00 00 40 00 00 04 C5 00 02 16
					39 00 00 40 00 00 04 C6 00 0A 14
					39 00 00 40 00 00 04 C7 02 02 02
					39 00 00 40 00 00 04 C8 06 00 06
					39 00 00 40 00 00 04 C9 05 02 02
					39 00 00 40 00 00 04 CA 00 00 00
					39 00 00 40 00 00 04 CB 04 04 03
					39 00 00 40 00 00 04 CC 02 02 02
					39 00 00 40 00 00 04 CD 00 00 00
					39 00 00 40 00 00 04 CE 0C 0C 0E
					39 00 00 40 00 00 04 CF 06 06 06
					39 00 00 40 00 00 04 D0 04 06 04
					39 00 00 40 00 00 04 D1 02 02 02
					39 00 00 40 00 00 04 D2 12 12 12
					39 00 00 40 00 00 04 D3 12 12 12
					39 00 00 40 00 00 04 D4 14 16 14
					39 00 00 40 00 00 04 D5 06 06 0A
					39 00 00 40 00 00 04 D6 02 02 06
					39 00 00 40 00 00 04 D7 1D 24 1E
					39 00 00 40 00 00 04 D8 16 1E 1A
					39 00 00 40 00 00 04 D9 12 1A 18
					39 00 00 40 00 00 04 DA 02 04 10
					39 00 00 40 00 00 04 DB FD 02 0A
					39 00 00 40 00 00 04 DC FD 00 00
					39 00 00 40 00 00 04 DD 12 18 1D
					39 00 00 40 00 00 04 DE 14 1B 1E
					39 00 00 40 00 00 04 DF 10 1A 1D
					39 00 00 40 00 00 04 E0 10 1A 14
					39 00 00 40 00 00 04 E1 02 0A 06
					39 00 00 40 00 00 04 E2 FD 02 02
					39 00 00 40 00 00 04 E3 FD 02 02
					39 00 00 40 00 00 04 E4 14 18 1C
					39 00 00 40 00 00 04 E5 10 1A 1A
					39 00 00 40 00 00 04 E6 1A 14 16
					39 00 00 40 00 00 04 E7 18 16 1C
					39 00 00 40 00 00 04 E8 14 10 10
					39 00 00 40 00 00 04 E9 0C 0E 12
					39 00 00 40 00 00 04 EA 14 12 10
					39 00 00 40 00 00 04 EB 02 02 02
					39 00 00 40 00 00 04 FF 5A A5 5C
					39 00 00 40 00 00 04 80 03 01 00
					39 00 00 40 00 00 04 81 04 02 02
					39 00 00 40 00 00 04 82 00 00 00
					39 00 00 40 00 00 04 83 01 03 02
					39 00 00 40 00 00 04 84 02 02 02
					39 00 00 40 00 00 04 85 00 00 00
					39 00 00 40 00 00 04 86 0E 10 0E
					39 00 00 40 00 00 04 87 06 06 06
					39 00 00 40 00 00 04 88 06 06 06
					39 00 00 40 00 00 04 89 02 02 02
					39 00 00 40 00 00 04 8A 16 16 14
					39 00 00 40 00 00 04 8B 16 18 14
					39 00 00 40 00 00 04 8C 14 16 12
					39 00 00 40 00 00 04 8D 0E 0E 0C
					39 00 00 40 00 00 04 8E 06 08 06
					39 00 00 40 00 00 04 8F 10 14 1C
					39 00 00 40 00 00 04 90 16 1E 18
					39 00 00 40 00 00 04 91 14 1A 16
					39 00 00 40 00 00 04 92 0D 12 10
					39 00 00 40 00 00 04 93 F2 06 04
					39 00 00 40 00 00 04 94 F2 06 04
					39 00 00 40 00 00 04 95 12 12 18
					39 00 00 40 00 00 04 96 12 10 1E
					39 00 00 40 00 00 04 97 12 18 1E
					39 00 00 40 00 00 04 98 12 1D 20
					39 00 00 40 00 00 04 99 12 1D 18
					39 00 00 40 00 00 04 9A F2 06 04
					39 00 00 40 00 00 04 9B F2 06 04
					39 00 00 40 00 00 04 9C 12 16 12
					39 00 00 40 00 00 04 9D 18 1E 12
					39 00 00 40 00 00 04 9E 14 1C 12
					39 00 00 40 00 00 04 9F 10 12 16
					39 00 00 40 00 00 04 A0 12 12 1C
					39 00 00 40 00 00 04 A1 12 12 0E
					39 00 00 40 00 00 04 A2 0E 10 0C
					39 00 00 40 00 00 04 A3 06 08 06
					39 00 00 40 00 00 04 A4 02 00 00
					39 00 00 40 00 00 04 A5 02 02 02
					39 00 00 40 00 00 04 A6 00 00 00
					39 00 00 40 00 00 04 A7 01 01 00
					39 00 00 40 00 00 04 A8 02 02 02
					39 00 00 40 00 00 04 A9 00 00 00
					39 00 00 40 00 00 04 AA 04 06 05
					39 00 00 40 00 00 04 AB 08 08 06
					39 00 00 40 00 00 04 AC 06 06 06
					39 00 00 40 00 00 04 AD 04 06 02
					39 00 00 40 00 00 04 AE 14 16 16
					39 00 00 40 00 00 04 AF 12 1A 14
					39 00 00 40 00 00 04 B0 14 16 12
					39 00 00 40 00 00 04 B1 04 04 0C
					39 00 00 40 00 00 04 B2 06 02 06
					39 00 00 40 00 00 04 B3 18 1A 1C
					39 00 00 40 00 00 04 B4 1A 1E 18
					39 00 00 40 00 00 04 B5 18 1A 14
					39 00 00 40 00 00 04 B6 06 04 0E
					39 00 00 40 00 00 04 B7 00 02 02
					39 00 00 40 00 00 04 B8 FE 00 00
					39 00 00 40 00 00 04 B9 0D 1D 1C
					39 00 00 40 00 00 04 BA 12 1D 1E
					39 00 00 40 00 00 04 BB 14 13 15
					39 00 00 40 00 00 04 BC 04 0C 0B
					39 00 00 40 00 00 04 BD 04 0C 0B
					39 00 00 40 00 00 04 BE FE 02 02
					39 00 00 40 00 00 04 BF FE 02 02
					39 00 00 40 00 00 04 C0 12 18 16
					39 00 00 40 00 00 04 C1 16 12 10
					39 00 00 40 00 00 04 C2 1C 16 1C
					39 00 00 40 00 00 04 C3 10 14 16
					39 00 00 40 00 00 04 C4 14 0A 1C
					39 00 00 40 00 00 04 C5 0E 08 10
					39 00 00 40 00 00 04 C6 0A 04 0A
					39 00 00 40 00 00 04 C7 00 00 00
					39 00 00 40 00 00 04 C8 04 04 04
					39 00 00 40 00 00 04 C9 0A 04 04
					39 00 00 40 00 00 04 CA 0A 04 04
					39 00 00 40 00 00 04 CB 0A 04 04
					39 00 00 40 00 00 04 CC 00 00 00
					39 00 00 40 00 00 04 CD 01 01 01
					39 00 00 40 00 00 04 CE 02 00 00
					39 00 00 40 00 00 04 CF 02 01 01
					39 00 00 00 00 00 04 FF 5A A5 00
					// ctb impro
					39 00 00 40 00 00 04 FF 5A A5 31
					39 00 00 40 00 00 0B 90 02 03 05 07 0A 02 03 05 07 0A
					39 00 00 40 00 00 19 8C 21 13 0C 0B 08 04 00 00 00 00 00 00 00 00 00 00 00 00 00 00 00 00 00 00
					39 00 00 40 00 00 1A 8D 16 0A 06 00 00 00 00 00 00 00 00 00 00 00 00 00 00 00 00 00 00 00 00 00 00
					39 00 00 40 00 00 09 8F 40 40 40 40 40 40 40 40
					15 00 00 40 00 00 02 D0 81
					39 00 00 40 00 00 13 80 F0 92 24 18 02 FE E8 DC 6E E0 10 0A 05 00 00 FA F6 F3
					39 00 00 40 00 00 13 81 F0 5C 24 16 02 FE EA DC A4 E0 0A 09 05 00 00 FE FB F0
					39 00 00 40 00 00 13 82 F0 48 24 11 02 FE EF DC B8 E0 0E 09 05 00 00 FF F7 F4
					39 00 00 40 00 00 13 83 F0 44 2C 10 02 FE F0 D4 BC E0 13 0D 05 00 00 FF FA F8
					39 00 00 40 00 00 13 86 F0 92 24 18 02 FE E8 DC 6E E0 10 0A 05 00 00 FA F6 F3
					39 00 00 40 00 00 13 87 F0 5C 24 16 02 FE EA DC A4 E0 0A 09 05 00 00 FE FB F0
					39 00 00 40 00 00 13 88 F0 48 24 11 02 FE EF DC B8 E0 0E 09 05 00 00 FF F7 F4
					39 00 00 40 00 00 13 89 F0 44 2C 10 02 FE F0 D4 BC E0 13 0D 05 00 00 FF FA F8
					15 00 00 40 00 00 02 D0 80
					39 00 00 00 01 00 04 FF 5A A5 00
					// te shift on
					39 00 00 40 00 00 04 FF 5A A5 02
					39 00 00 40 00 00 03 AB AF 82
					// ddic corner Hole
					39 00 00 40 00 00 04 FF 5A A5 13
					39 00 00 40 00 00 02 F9 4C //HOLE OFF
					39 00 00 40 00 00 04 FF 5A A5 17
					15 00 00 40 00 00 02 A0 0E //RCN OFF
					// pps table
					39 00 00 40 00 00 04 FF 5A A5 07
					15 00 00 40 00 00 02 8A 01
					39 00 00 40 00 00 03 8B 21 E0
					39 00 00 40 00 00 64 80 00 00 00 00 00 12 00 00 AB 30 80 0A D4 04 F8 00 16 02 7C 02 7C 02 00 02 59 00 20 02 2E 00 08 00 0D 04 F4 03 ED 18 00 10 F0 07 10 20 00 06 0F 0F 33 0E 1C 2A 38 46 54 62 69 70 77 79 7B 7D 7E 02 02 22 00 2A 40 2A BE 3A FC 3A FA 3A F8 3B 38 3B 78 3B B6 4B B6 4B F4 4B F4 6C 34 84 74 00 00 00 00 00 00
					39 00 00 40 00 00 64 81 00 00 00 00 00 12 00 00 AB 21 00 0A D4 04 F8 00 16 02 7C 02 7C 01 55 01 D7 00 0A 01 2D 00 35 00 0D 04 F4 16 3B 08 00 0C 00 07 10 20 00 06 0F 0F 33 0E 1C 2A 38 46 54 62 69 70 77 79 7B 7D 7E 00 82 11 40 19 C0 22 3E 32 7C 3A BA 3A F8 3B 38 3B 38 3B 76 4B 76 4B 74 4B 74 5B B4 73 F4 01 00 00 00 00 00
					39 00 00 40 00 00 04 FF 5A A5 07
					15 00 00 40 00 00 02 91 00         //Ycrcb
					39 00 00 40 00 00 04 FF 5A A5 14
					15 00 00 40 00 00 02 82 01       //SPR IN AP ON
					39 00 00 40 00 00 04 FF 5A A5 14
					15 00 00 40 00 00 02 80 00      //DDIC SPR OFF
					39 00 00 40 00 00 04 FF 5A A5 00
					39 00 00 40 00 00 04 FF 5A A5 06
					15 00 00 40 00 00 02 A0 00 //ESD fixed
					15 00 00 40 00 00 02 C6 01 //1bit ESD check
					39 00 00 40 00 00 04 FF 5A A5 08
					15 00 00 40 00 00 02 D2 05
					15 00 00 40 00 00 02 D3 01
					15 00 00 40 00 00 02 E0 22 // crc reset
					39 00 00 40 00 00 09 ED FF FF FF FF FF FF 45 FF
					39 00 00 40 00 00 09 EE FF FD FF FD F9 FA BE 76
					// osc fixed Auto trim TE
					39 00 00 40 00 00 04 FF 5A A5 22
					39 00 00 40 00 00 08 D8 00 FF 11 10 3C 18 18
					39 00 00 40 00 00 08 D9 00 BE 11 10 3C 12 12
					39 00 00 40 00 00 0A DC 84 94 BB 00 20 C4 A1 CC 10
					15 00 00 40 00 00 02 DD 01
					15 00 00 40 00 00 02 DE F1
					15 00 00 40 00 00 02 DF 80
					39 00 00 40 00 00 07 E0 02 00 5F 21 00 28
					39 00 00 40 00 00 04 FF 5A A5 00
					15 00 00 40 00 00 02 7D 00
					39 00 00 40 00 00 04 FF 5A A5 00
					15 00 00 40 00 00 02 5E 01
					15 00 00 40 00 00 02 60 00
					15 00 00 40 00 00 02 61 07
					15 00 00 40 00 00 02 6D 01
					15 00 00 40 00 00 02 35 00
					15 00 00 40 00 00 02 53 20
					// timing switch
					39 00 00 40 00 00 04 FF 5A A5 00
					15 00 00 40 00 00 02 60 00
					15 00 00 40 00 00 02 7D 00
					39 00 00 40 00 00 04 FF 5A A5 2D
					39 00 00 40 00 00 03 83 00 00
					15 00 00 40 00 00 02 F2 00
					// odc on
					39 00 00 40 00 00 04 FF 5A A5 49
					15 00 00 40 00 00 02 E0 01
					// dvdd sleep in
					39 00 00 40 00 00 04 FF 5A A5 1F
					39 00 00 40 00 00 05 96 15 30 03 01
					39 00 00 40 00 00 19 83 20 23 21 1E 1F 00 00 00 1E 1F 00 00 20 1F 20 23 20 00 00 00 00 00 00 00
					39 00 00 40 00 00 19 8F 0F 06 78 0E 11 00 00 00 0E 11 00 00 00 10 02 06 06 00 00 00 00 00 00 00
					39 00 00 40 00 00 04 FF 5A A5 00
					// pull dowm pmic
					39 00 00 40 00 00 04 FF 5A A5 1C
					39 00 00 40 00 00 16 E1 10 80 9A 65 59 54 69 95 56 6A 55 99 9A 55 55 25 58 55 66 A2 00
					39 00 00 40 00 00 04 FF 5A A5 05
					15 00 00 40 00 00 02 83 01
					// LGOCB change to 30
					39 00 00 40 00 00 04 FF 5A A5 53
					39 00 00 40 00 00 1F A2 10 10 10 10 10 10 10 10 30 30 10 10 10 10 10 10 10 10 30 30 10 10 10 10 10 10 10 10 30 30
					39 00 00 00 00 00 04 FF 5A A5 00
					//Light On
					39 00 00 00 78 00 01 11 // Sleep out
					39 00 00 40 00 00 04 FF 5A A5 00
					39 00 00 00 00 00 01 29 // Display out
				];
				oplus,dsi-aod-off-command = [
					39 00 00 00 00 00 04 FF 5A A5 00
					39 00 00 00 00 00 02 38 00
					39 00 00 00 00 00 05 51 00 00 00 00
					39 00 00 00 00 00 04 FF 5A A5 51
					39 00 00 00 00 00 07 A6 C7 C3 C3 C3 22 22
					39 00 00 00 00 00 04 FF 5A A5 52
					39 00 00 00 00 00 07 86 46 46 46 46 00 00
					39 00 00 00 00 00 04 FF 5A A5 02
					39 00 00 00 00 00 03 AB AF 82
				];
				oplus,dsi-ultra-low-power-aod-on-command = [
					39 00 00 00 00 00 04 FF 5A A5 2D
					39 00 00 00 00 00 03 8A 02 00
					39 00 00 00 00 00 04 FF 5A A5 00
				];
				oplus,dsi-ultra-low-power-aod-off-command = [
					39 00 00 00 00 00 04 FF 5A A5 2D
					39 00 00 00 00 00 03 8A 00 00
					39 00 00 00 00 00 04 FF 5A A5 00
				];
				oplus,dsi-hbm-on-command = [
					39 00 00 00 00 00 03 51 0E 7A
				];
				oplus,dsi-hbm-off-command = [
					39 00 00 00 00 00 03 51 0D BB
				];
				oplus,dsi-pwm-switch-1to3pul-command = [
				];
				oplus,dsi-pwm-switch-3to1pul-command = [
				];
				oplus,dsi-adfr-min-fps-120hz-command = [
					39 00 00 40 00 00 04 FF 5A A5 2D
					39 00 00 40 00 00 03 83 00 00
					39 00 00 00 00 00 04 FF 5A A5 00
				];
				oplus,dsi-adfr-min-fps-30hz-command = [
					39 00 00 40 00 00 04 FF 5A A5 2D
					39 00 00 40 00 00 03 83 03 00
					39 00 00 00 00 00 04 FF 5A A5 00
				];
				oplus,dsi-multi-te-enable-command = [
					39 00 00 40 00 00 04 FF 5A A5 20
					39 00 00 00 00 00 02 BC 96
				];
				oplus,dsi-multi-te-disable-command = [
					39 00 00 40 00 00 04 FF 5A A5 20
					39 00 00 40 00 00 02 BC 06
					39 00 00 40 00 00 04 FF 5A A5 02
					39 00 00 00 00 00 09 B0 00 80 00 10 00 00 00 00
				];

				oplus,dsi-timing-switch-command-state = "dsi_hs_mode";
				oplus,dsi-timing-switch-1pulse-command-state = "dsi_hs_mode";
				oplus,dsi-on-command-state = "dsi_lp_mode";
				oplus,dsi-aod-off-command-state = "dsi_ls_mode";
				oplus,dsi-ultra-low-power-aod-on-command-state = "dsi_ls_mode";
				oplus,dsi-ultra-low-power-aod-off-command-state = "dsi_ls_mode";
				oplus,dsi-hbm-on-command-state = "dsi_hs_mode";
				oplus,dsi-hbm-off-command-state = "dsi_hs_mode";
				oplus,dsi-pwm-switch-1to3pul-command-state = "dsi_hs_mode";
				oplus,dsi-pwm-switch-3to1pul-command-state = "dsi_hs_mode";
				oplus,dsi-adfr-min-fps-120hz-command-state = "dsi_hs_mode";
				oplus,dsi-adfr-min-fps-30hz-command-state = "dsi_hs_mode";
				oplus,dsi-multi-te-enable-command-state = "dsi_hs_mode";
				oplus,dsi-multi-te-disable-command-state = "dsi_hs_mode";
				oplus,dsc-params-entries = <&dsc_params>;
				oplus,spr-params-entries = <&spr_params>;
				oplus,dyn-fps {
					switch_en = <1>;
					vact_timing_fps = <120>;
					apollo_limit_superior_us = <4900>;
					apollo_limit_inferior_us = <6750>;
					apollo_transfer_time_us = <6400>;
				};
				oplus,display-mode {
					oplus,display-mode@0 {
						hdisplay = <1272>;
						vdisplay = <2772>;
						fhd-hfp = <2>;
						fhd-hsa = <26>;
						fhd-hbp = <36>;
						fhd-vfp = <100>;
						fhd-vsa = <8>;
						fhd-vbp = <76>;
						hskew = <OPLUS_ADFR>;
					};
					oplus,display-mode@1 {
						hdisplay = <1080>;
						vdisplay = <2354>;
						fhd-hfp = <2>;
						fhd-hsa = <26>;
						fhd-hbp = <36>;
						fhd-vfp = <100>;
						fhd-vsa = <8>;
						fhd-vbp = <76>;
						hskew = <OPLUS_ADFR>;
					};
				};
			};
		};
	};
};

&panel_ac283_p_7_a0020_dsi_cmd {
	oplus,dsi-display-panel@0 {
		res-switch = <2>;
		/* Hardware config */
		oplus,panel-supply-entries = <&dsi_panel_pwr_supply>;
		oplus,panel-power-on-sequence = "1", "vddi", "5", "vddr", "1", "1p2", "5", "vci", "1";
		oplus,panel-power-off-sequence = "2", "vci", "5", "1p2", "1", "vddr", "5", "vddi", "1";
		reset-gpios = <&pio 89 0>;
		oplus,panel-reset-sequence = <2 10>, <1 1>, <0 1>, <1 20>;
		oplus,pmic_reset_enable;
		pmic-reset-gpios = <&pio 79 0>;
		/* Panel config */
		oplus,dsi-serial-number-enabled=<1>;
		oplus,dsi-serial-number-switch-page;
		oplus,dsi-serial-number-index= <0>;
		oplus,dsi-serial-number-switch-page-command= <0xFF 0x5A 0xA5 0x1D>;
		oplus,dsi-serial-number-default-switch-page-command= <0xFF 0x5A 0xA5 0x00>;
		oplus,dsi-serial-number-reg= <0x80>;
		oplus,dsi-serial-number-read-count= <7>;
		oplus,dsi-serial-number-year-offset= <0>;
		/* btb-sn config */
		oplus,dsi-btb-sn-enabled;
		oplus,dsi-btb-sn-switch-page;
		oplus,dsi-btb-sn-reg= <0x82>;
		oplus,dsi-btb-sn-index= <0>;
		oplus,dsi-btb-sn-read-count= <32>;
		oplus,mode-switch-h2l-delay;
		oplus,keep_ulps = <1>;
		/* PWM config */
		oplus,pwm-turbo-support = <1>; /* 0 not support, 1 with switch, 2 Global high frequency pwm without switch */
		oplus,pwm-switch-backlight-threshold = <1155>;
		oplus,pwm-onepulse-support = <1>;
		oplus,pwm-onepulse-enabled = <0>;
		oplus,pwm-turbo-wait-te = <1>;
		/* ADFR config */
		oplus-adfr-config = <0x4201>;
		/* DBI config */
		oplus,is-support-dbi;
		/* OFP config */
		oplus,ofp-fp-type = <0x1c0>;
		oplus,ofp-longrui-aod-config = <0x0E>;
		/* ext_params */
		oplus,panel-type = <2>;
		oplus,lane-swap-en = <0>;
		oplus,lane-swap = <
			MIPITX_PHY_LANE_0 MIPITX_PHY_LANE_1 MIPITX_PHY_LANE_3 MIPITX_PHY_LANE_2 MIPITX_PHY_LANE_CK MIPITX_PHY_LANE_0
			MIPITX_PHY_LANE_0 MIPITX_PHY_LANE_1 MIPITX_PHY_LANE_3 MIPITX_PHY_LANE_2 MIPITX_PHY_LANE_CK MIPITX_PHY_LANE_0
		>;
		oplus,lcm-color-mode = <MTK_DRM_COLOR_MODE_DISPLAY_P3>;
		oplus,output-mode = <MTK_PANEL_DSC_SINGLE_PORT>;
		oplus,panel-bpp = <10>;
		oplus,physical-width-um = <71868>;
		oplus,physical-height-um = <156618>;
		/* color */
		oplus,color-vivid-status;
		oplus,color-srgb-status;
		// oplus,color-softiris-status;
		// oplus,color-dual-panel-status;
		oplus,color-dual-brightness-status;
		oplus,color-oplus-calibrate-status;
		// oplus,color-samsung-status;
		oplus,color-loading-status;
		oplus,color-2nit-status;
		// oplus,color-nature-profession-status;
		/* ESD */
		oplus,cust-esd-check = <0>; // both check TE and reg
		oplus,esd-check-enable = <1>;
		oplus,esd_check_cmd = [
			0A
		];
		oplus,esd_check_count = [
			01
		];
		oplus,esd_check_value = [
			9C
		];
		oplus,esd_check_mask = [
			FF
		];
		/* MIPI error check config */
		/*
		 ** BIT(0): enable/disable check
		 ** BIT(1): enable/disable page switch
		 */
		oplus,mipi-err-check-config = <0x01>; // 0b0000'0111
		oplus,mipi-err-check-reg = [
			0E
		];
		oplus,mipi-err-check-value = [
			80
		];
		oplus,mipi-err-check-count = [
			01
		];
		/*  32-bit binary flag
		 ** Bit value identified how to match the return value of each register.
		 ** The value 0(default) means equal, and the value 1 means not equal.
		 */
		oplus,mipi-err-check-match-modes = <0x00000000>;
	};
};
